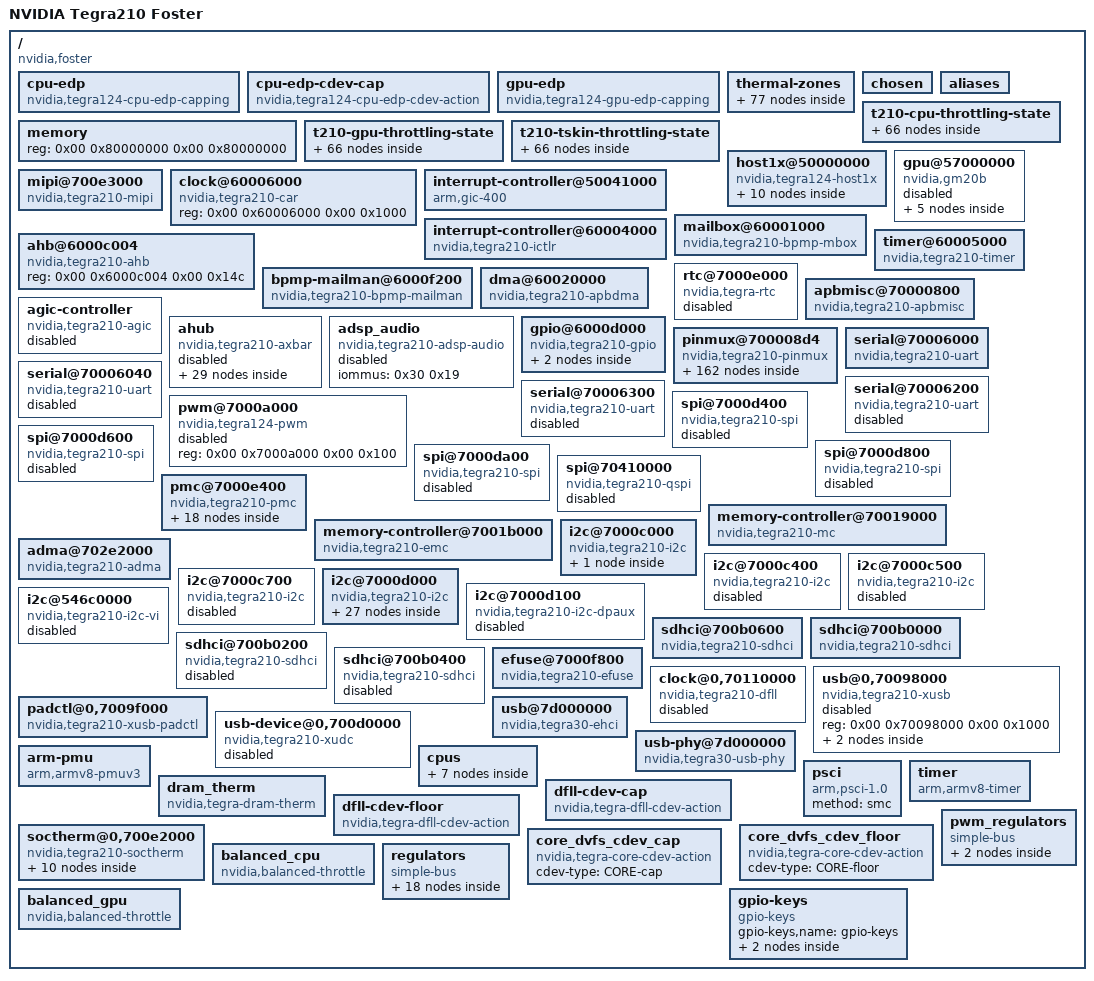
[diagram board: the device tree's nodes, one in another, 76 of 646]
/dts-v1/;

/ {
	#address-cells = <0x02>;
	#size-cells = <0x02>;
	compatible = "nvidia,foster\0nvidia,tegra210";
	interrupt-parent = <0x01>;
	model = "NVIDIA Tegra210 Foster";

	cpu-edp {
		compatible = "nvidia,tegra124-cpu-edp-capping";
		nvidia,freq-step = <0x124f800>;
		nvidia,tegra-ppm-cdyn = <0xe7ef0 0x15be68 0x286f90 0x2faf08>;
		nvidia,tegra-ppm-leakage_weights = <0x1d6 0x29e 0x37a 0x41a>;
		nvidia,tegra-ppm-min_leakage = <0x1e>;
		nvidia,tegra-ppm-coeff_scale = <0x3e8>;
		nvidia,tegra-ppm-leakage_coeffs = <0xffc82924 0xffd15972 0x188c70 0xfffe0053 0x00 0xfe9296 0xff9ec369 0x76883 0xdf9e1a 0xfe718cfb 0x7d365d 0xfff6fa5b 0xff5d899f 0xbbd7ba 0xffcbfa66 0x3958e 0xff87e7c6 0x8b1416 0xffd7e55c 0x2d28a 0x23f3784 0xfdd26ebd 0x948221 0xfff5df7d 0xfcb4b1d2 0x2d60663 0xff4afd55 0xbfe6c 0x17e635c 0xfed015c0 0x47eafe 0xfffb5b77 0x6941d8 0xffaff1ed 0x127eea 0xfffecc39 0xfe70f0f7 0x12565d9 0xffbe1614 0x4381d 0x1f004d1 0xfe9e0b74 0x4d73de 0xfffb1db3 0xff3780c3 0x8ba0fd 0xffe229eb 0x1daf0 0xfff38a0a 0x8b4fd 0xfffe1d49 0x1e56 0x2d5f9e 0xffe0d6d7 0x6a1be 0xffff9672 0xffc99836 0x24c1ff 0xfff84f1f 0x791b 0x155857 0xfff1c880 0x2ed60 0xffffd261>;
		nvidia,tz = <0x02>;
		linux,phandle = <0x03>;
		phandle = <0x03>;
	};

	cpu-edp-cdev-cap {
		compatible = "nvidia,tegra124-cpu-edp-cdev-action";
		act-dev = <0x03>;
		cdev-type = "CPU-EDP-cap";
		#cooling-cells = <0x02>;
		linux,phandle = <0x07>;
		phandle = <0x07>;
	};

	gpu-edp {
		compatible = "nvidia,tegra124-gpu-edp-capping";
		nvidia,freq-step = <0x249f000>;
		nvidia,tegra-ppm-cdyn = <0xe92780>;
		nvidia,tegra-ppm-min_leakage = <0x1e>;
		nvidia,tegra-ppm-coeff_scale = <0x2710>;
		nvidia,tegra-ppm-leakage_coeffs = <0xfef8e2c1 0x17e889a 0xffbd9c0b 0xb807 0x00 0xfd0f73bb 0x864faf 0x1ee25 0x3edf207 0xd7d9e8 0xffd1cab2 0xfff8d56d 0xfd1d9b5f 0x987ac7 0xffeabd12 0x476ae 0x1763b9c 0xfe680f80 0x36f8cb 0x130f 0xfd61d8f9 0x3f7f583 0xff814d99 0xfffd13a0 0x00 0xfd623768 0x4185ff 0x6d6dc 0x119f867 0x4970a8 0x3ae07 0xfffc45c6 0xfdb3616c 0x167f6fb 0xffcc920a 0x198d0 0x6fc1a76 0xfbb7a001 0x9aade2 0xfffb7d5a 0xf93967d1 0x42ae62d 0xff6c4452 0x3ddd8 0x216db9c 0xfeb57ac0 0x2cae38 0xffff05da 0x5961d4 0xffcc181f 0x7ce63 0xffffaed8 0xfee6666e 0xa37bad 0xffe7820c 0xfb9f 0x11f79af 0xff5931b1 0x18dc9f 0xffff04f7 0xffa0fde9 0x371c8a 0xfff7d487 0x50ba>;
		nvidia,tz = <0x04>;
		linux,phandle = <0x34>;
		phandle = <0x34>;
	};

	thermal-zones {
		status = "okay";

		cpu {
			polling-delay-passive = <0x3e8>;
			polling-delay = <0x00>;
			thermal-sensors = <0x05 0x00>;
			linux,phandle = <0x02>;
			phandle = <0x02>;

			trips {

				cpu_edp@23 {
					temperature = <0x59d8>;
					hysteresis = <0x3e8>;
					type = "active";
					linux,phandle = <0x06>;
					phandle = <0x06>;
				};

				cpu_edp@40 {
					temperature = <0x9c40>;
					hysteresis = <0x3e8>;
					type = "active";
					linux,phandle = <0x08>;
					phandle = <0x08>;
				};

				cpu_edp@50 {
					temperature = <0xc350>;
					hysteresis = <0x3e8>;
					type = "active";
					linux,phandle = <0x09>;
					phandle = <0x09>;
				};

				cpu_edp@60 {
					temperature = <0xea60>;
					hysteresis = <0x3e8>;
					type = "active";
					linux,phandle = <0x0a>;
					phandle = <0x0a>;
				};

				cpu_edp@70 {
					temperature = <0x11170>;
					hysteresis = <0x3e8>;
					type = "active";
					linux,phandle = <0x0b>;
					phandle = <0x0b>;
				};

				cpu_edp@74 {
					temperature = <0x12110>;
					hysteresis = <0x3e8>;
					type = "active";
					linux,phandle = <0x0c>;
					phandle = <0x0c>;
				};

				cpu_edp@78 {
					temperature = <0x130b0>;
					hysteresis = <0x3e8>;
					type = "active";
					linux,phandle = <0x0d>;
					phandle = <0x0d>;
				};

				cpu_edp@82 {
					temperature = <0x14050>;
					hysteresis = <0x3e8>;
					type = "active";
					linux,phandle = <0x0e>;
					phandle = <0x0e>;
				};

				cpu_edp@86 {
					temperature = <0x14ff0>;
					hysteresis = <0x3e8>;
					type = "active";
					linux,phandle = <0x0f>;
					phandle = <0x0f>;
				};

				cpu_edp@90 {
					temperature = <0x15f90>;
					hysteresis = <0x3e8>;
					type = "active";
					linux,phandle = <0x10>;
					phandle = <0x10>;
				};

				cpu_edp@94 {
					temperature = <0x16f30>;
					hysteresis = <0x3e8>;
					type = "active";
					linux,phandle = <0x11>;
					phandle = <0x11>;
				};

				cpu_edp@98 {
					temperature = <0x17ed0>;
					hysteresis = <0x3e8>;
					type = "active";
					linux,phandle = <0x12>;
					phandle = <0x12>;
				};

				cpu_edp@102 {
					temperature = <0x18e70>;
					hysteresis = <0x3e8>;
					type = "active";
					linux,phandle = <0x13>;
					phandle = <0x13>;
				};

				dfll-floor-trip0 {
					temperature = <0x3a98>;
					hysteresis = <0x3e8>;
					type = "active";
					linux,phandle = <0x14>;
					phandle = <0x14>;
				};

				dfll-floor-trip1 {
					temperature = <0x7530>;
					hysteresis = <0x3e8>;
					type = "active";
					linux,phandle = <0x16>;
					phandle = <0x16>;
				};

				dfll-floor-trip2 {
					temperature = <0xc350>;
					hysteresis = <0x3e8>;
					type = "active";
					linux,phandle = <0x17>;
					phandle = <0x17>;
				};

				dfll-floor-trip3 {
					temperature = <0x11170>;
					hysteresis = <0x3e8>;
					type = "active";
					linux,phandle = <0x18>;
					phandle = <0x18>;
				};

				dfll-cap-trip0 {
					temperature = <0x101d0>;
					hysteresis = <0x3e8>;
					type = "active";
					linux,phandle = <0x19>;
					phandle = <0x19>;
				};

				dfll-cap-trip1 {
					temperature = <0x14ff0>;
					hysteresis = <0x3e8>;
					type = "active";
					linux,phandle = <0x1b>;
					phandle = <0x1b>;
				};

				core_dvfs_floor_trip0 {
					temperature = <0x3a98>;
					hysteresis = <0x3e8>;
					type = "active";
					linux,phandle = <0x1c>;
					phandle = <0x1c>;
				};

				core_dvfs_cap_trip0 {
					temperature = <0x14ff0>;
					hysteresis = <0x3e8>;
					type = "active";
					linux,phandle = <0x1e>;
					phandle = <0x1e>;
				};
			};

			cooling-maps {

				map_cpu_edp_23 {
					trip = <0x06>;
					cooling-device = <0x07 0x17 0x17>;
				};

				map_cpu_edp_40 {
					trip = <0x08>;
					cooling-device = <0x07 0x28 0x28>;
				};

				map_cpu_edp_50 {
					trip = <0x09>;
					cooling-device = <0x07 0x32 0x32>;
				};

				map_cpu_edp_60 {
					trip = <0x0a>;
					cooling-device = <0x07 0x3c 0x3c>;
				};

				map_cpu_edp_70 {
					trip = <0x0b>;
					cooling-device = <0x07 0x46 0x46>;
				};

				map_cpu_edp_74 {
					trip = <0x0c>;
					cooling-device = <0x07 0x4a 0x4a>;
				};

				map_cpu_edp_78 {
					trip = <0x0d>;
					cooling-device = <0x07 0x4e 0x4e>;
				};

				map_cpu_edp_82 {
					trip = <0x0e>;
					cooling-device = <0x07 0x52 0x52>;
				};

				map_cpu_edp_86 {
					trip = <0x0f>;
					cooling-device = <0x07 0x56 0x56>;
				};

				map_cpu_edp_90 {
					trip = <0x10>;
					cooling-device = <0x07 0x5a 0x5a>;
				};

				map_cpu_edp_94 {
					trip = <0x11>;
					cooling-device = <0x07 0x5e 0x5e>;
				};

				map_cpu_edp_98 {
					trip = <0x12>;
					cooling-device = <0x07 0x62 0x62>;
				};

				map_cpu_edp_102 {
					trip = <0x13>;
					cooling-device = <0x07 0x66 0x66>;
				};

				map0 {
					trip = <0x14>;
					cooling-device = <0x15 0x01 0x01>;
				};

				map1 {
					trip = <0x16>;
					cooling-device = <0x15 0x02 0x02>;
				};

				map2 {
					trip = <0x17>;
					cooling-device = <0x15 0x03 0x03>;
				};

				map3 {
					trip = <0x18>;
					cooling-device = <0x15 0x04 0x04>;
				};

				map5 {
					trip = <0x19>;
					cooling-device = <0x1a 0x01 0x01>;
				};

				map6 {
					trip = <0x1b>;
					cooling-device = <0x1a 0x02 0x02>;
				};

				core_dvfs_floor_map0 {
					trip = <0x1c>;
					cooling-device = <0x1d 0x01 0x01>;
				};

				core_dvfs_cap_map0 {
					trip = <0x1e>;
					cooling-device = <0x1f 0x01 0x01>;
				};
			};
		};

		gpu {
			polling-delay-passive = <0x3e8>;
			polling-delay = <0x00>;
			thermal-sensors = <0x05 0x02>;
			linux,phandle = <0x04>;
			phandle = <0x04>;

			trips {

				gpu_edp@20 {
					temperature = <0x4e20>;
					hysteresis = <0x3e8>;
					type = "active";
					linux,phandle = <0x20>;
					phandle = <0x20>;
				};

				gpu_edp@35 {
					temperature = <0x88b8>;
					hysteresis = <0x3e8>;
					type = "active";
					linux,phandle = <0x22>;
					phandle = <0x22>;
				};

				gpu_edp@50 {
					temperature = <0xc350>;
					hysteresis = <0x3e8>;
					type = "active";
					linux,phandle = <0x23>;
					phandle = <0x23>;
				};

				gpu_edp@70 {
					temperature = <0x11170>;
					hysteresis = <0x3e8>;
					type = "active";
					linux,phandle = <0x24>;
					phandle = <0x24>;
				};

				gpu_edp@80 {
					temperature = <0x13880>;
					hysteresis = <0x3e8>;
					type = "active";
					linux,phandle = <0x25>;
					phandle = <0x25>;
				};

				gpu_edp@90 {
					temperature = <0x15f90>;
					hysteresis = <0x3e8>;
					type = "active";
					linux,phandle = <0x26>;
					phandle = <0x26>;
				};

				gpu_edp@95 {
					temperature = <0x17318>;
					hysteresis = <0x3e8>;
					type = "active";
					linux,phandle = <0x27>;
					phandle = <0x27>;
				};

				gpu_edp@100 {
					temperature = <0x186a0>;
					hysteresis = <0x3e8>;
					type = "active";
					linux,phandle = <0x28>;
					phandle = <0x28>;
				};

				gpu_edp@105 {
					temperature = <0x19a28>;
					hysteresis = <0x3e8>;
					type = "active";
					linux,phandle = <0x29>;
					phandle = <0x29>;
				};
			};

			cooling-maps {

				map_gpu_edp_20 {
					trip = <0x20>;
					cooling-device = <0x21 0x14 0x14>;
				};

				map_gpu_edp_35 {
					trip = <0x22>;
					cooling-device = <0x21 0x23 0x23>;
				};

				map_gpu_edp_50 {
					trip = <0x23>;
					cooling-device = <0x21 0x32 0x32>;
				};

				map_gpu_edp_70 {
					trip = <0x24>;
					cooling-device = <0x21 0x46 0x46>;
				};

				map_gpu_edp_80 {
					trip = <0x25>;
					cooling-device = <0x21 0x50 0x50>;
				};

				map_gpu_edp_90 {
					trip = <0x26>;
					cooling-device = <0x21 0x5a 0x5a>;
				};

				map_gpu_edp_95 {
					trip = <0x27>;
					cooling-device = <0x21 0x5f 0x5f>;
				};

				map_gpu_edp_100 {
					trip = <0x28>;
					cooling-device = <0x21 0x64 0x64>;
				};

				map_gpu_edp_105 {
					trip = <0x29>;
					cooling-device = <0x21 0x69 0x69>;
				};
			};
		};

		mem {
			polling-delay-passive = <0x00>;
			polling-delay = <0x00>;
			thermal-sensors = <0x05 0x01>;
		};

		pllx {
			polling-delay-passive = <0x00>;
			polling-delay = <0x00>;
			thermal-sensors = <0x05 0x03>;
		};

		dram {
			polling-delay-passive = <0x3e8>;
			polling-delay = <0x00>;
			thermal-sensors = <0x2a>;

			trips {

				trip0 {
					temperature = <0x04>;
					hysteresis = <0x00>;
					type = "passive";
					linux,phandle = <0x2b>;
					phandle = <0x2b>;
				};

				trip1 {
					temperature = <0x05>;
					hysteresis = <0x00>;
					type = "passive";
					linux,phandle = <0x2d>;
					phandle = <0x2d>;
				};

				trip2 {
					temperature = <0x06>;
					hysteresis = <0x00>;
					type = "passive";
					linux,phandle = <0x2e>;
					phandle = <0x2e>;
				};
			};

			cooling-maps {

				map0 {
					trip = <0x2b>;
					cooling-device = <0x2c 0x01 0x01>;
				};

				map1 {
					trip = <0x2d>;
					cooling-device = <0x2c 0x02 0x02>;
				};

				map2 {
					trip = <0x2e>;
					cooling-device = <0x2c 0x03 0x03>;
				};
			};
		};
	};

	chosen {
	};

	aliases {
		isp0 = "/host1x@50000000/ispa@54600000";
		isp1 = "/host1x@50000000/ispb@54680000";
		serial0 = "/serial@70006000";
		serial1 = "/serial@70006040";
		serial2 = "/serial@70006200";
		serial3 = "/serial@70006300";
		qspi6 = "/spi@70410000";
	};

	memory {
		device_type = "memory";
		reg = <0x00 0x80000000 0x00 0x80000000>;
	};

	t210-cpu-throttling-state {
		linux,phandle = <0x31>;
		phandle = <0x31>;

		throt-state@0 {
			cpu-freq = <0x1c677c>;
			gpu-freq = <0xd0408>;
			c3bus-freq = <0x7d000>;
			sclk-freq = <0x5dc00>;
		};

		throt-state@1 {
			cpu-freq = <0x1c03e0>;
			gpu-freq = <0xd0408>;
			c3bus-freq = <0x7d000>;
			sclk-freq = <0x5dc00>;
		};

		throt-state@2 {
			cpu-freq = <0x1ba044>;
			gpu-freq = <0xd0408>;
			c3bus-freq = <0x7d000>;
			sclk-freq = <0x5dc00>;
		};

		throt-state@3 {
			cpu-freq = <0x1b3ca8>;
			gpu-freq = <0xd0408>;
			c3bus-freq = <0x7d000>;
			sclk-freq = <0x5dc00>;
		};

		throt-state@4 {
			cpu-freq = <0x1ad90c>;
			gpu-freq = <0xd0408>;
			c3bus-freq = <0x7d000>;
			sclk-freq = <0x5dc00>;
		};

		throt-state@5 {
			cpu-freq = <0x1a7570>;
			gpu-freq = <0xd0408>;
			c3bus-freq = <0x7d000>;
			sclk-freq = <0x5dc00>;
		};

		throt-state@6 {
			cpu-freq = <0x1a11d4>;
			gpu-freq = <0xd0408>;
			c3bus-freq = <0x7d000>;
			sclk-freq = <0x5dc00>;
		};

		throt-state@7 {
			cpu-freq = <0x19ae38>;
			gpu-freq = <0xd0408>;
			c3bus-freq = <0x7d000>;
			sclk-freq = <0x5dc00>;
		};

		throt-state@8 {
			cpu-freq = <0x194a9c>;
			gpu-freq = <0xd0408>;
			c3bus-freq = <0x7d000>;
			sclk-freq = <0x5dc00>;
		};

		throt-state@9 {
			cpu-freq = <0x18e700>;
			gpu-freq = <0xd0408>;
			c3bus-freq = <0x7d000>;
			sclk-freq = <0x5dc00>;
		};

		throt-state@10 {
			cpu-freq = <0x188364>;
			gpu-freq = <0xccd58>;
			c3bus-freq = <0x7d000>;
			sclk-freq = <0x5dc00>;
		};

		throt-state@11 {
			cpu-freq = <0x181fc8>;
			gpu-freq = <0xc9a90>;
			c3bus-freq = <0x7d000>;
			sclk-freq = <0x5dc00>;
		};

		throt-state@12 {
			cpu-freq = <0x17bc2c>;
			gpu-freq = <0xc63e0>;
			c3bus-freq = <0x7d000>;
			sclk-freq = <0x5dc00>;
		};

		throt-state@13 {
			cpu-freq = <0x175890>;
			gpu-freq = <0xc2d30>;
			c3bus-freq = <0x7d000>;
			sclk-freq = <0x5dc00>;
		};

		throt-state@14 {
			cpu-freq = <0x16f4f4>;
			gpu-freq = <0xbf680>;
			c3bus-freq = <0x7d000>;
			sclk-freq = <0x5dc00>;
		};

		throt-state@15 {
			cpu-freq = <0x169158>;
			gpu-freq = <0xbc3b8>;
			c3bus-freq = <0x7d000>;
			sclk-freq = <0x5dc00>;
		};

		throt-state@16 {
			cpu-freq = <0x162dbc>;
			gpu-freq = <0xb8d08>;
			c3bus-freq = <0x7d000>;
			sclk-freq = <0x5dc00>;
		};

		throt-state@17 {
			cpu-freq = <0x15ca20>;
			gpu-freq = <0xb5658>;
			c3bus-freq = <0x7d000>;
			sclk-freq = <0x5dc00>;
		};

		throt-state@18 {
			cpu-freq = <0x156684>;
			gpu-freq = <0xb1fa8>;
			c3bus-freq = <0x7d000>;
			sclk-freq = <0x5dc00>;
		};

		throt-state@19 {
			cpu-freq = <0x1502e8>;
			gpu-freq = <0xaece0>;
			c3bus-freq = <0x7d000>;
			sclk-freq = <0x5dc00>;
		};

		throt-state@20 {
			cpu-freq = <0x149f4c>;
			gpu-freq = <0xab630>;
			c3bus-freq = <0x7d000>;
			sclk-freq = <0x5dc00>;
		};

		throt-state@21 {
			cpu-freq = <0x143bb0>;
			gpu-freq = <0xa7f80>;
			c3bus-freq = <0x7d000>;
			sclk-freq = <0x5dc00>;
		};

		throt-state@22 {
			cpu-freq = <0x13d814>;
			gpu-freq = <0xa48d0>;
			c3bus-freq = <0x7d000>;
			sclk-freq = <0x5dc00>;
		};

		throt-state@23 {
			cpu-freq = <0x137478>;
			gpu-freq = <0xa1608>;
			c3bus-freq = <0x7d000>;
			sclk-freq = <0x5dc00>;
		};

		throt-state@24 {
			cpu-freq = <0x1310dc>;
			gpu-freq = <0x9df58>;
			c3bus-freq = <0x7d000>;
			sclk-freq = <0x5dc00>;
		};

		throt-state@25 {
			cpu-freq = <0x12ad40>;
			gpu-freq = <0x9a8a8>;
			c3bus-freq = <0x7d000>;
			sclk-freq = <0x5dc00>;
		};

		throt-state@26 {
			cpu-freq = <0x1249a4>;
			gpu-freq = <0x975e0>;
			c3bus-freq = <0x7d000>;
			sclk-freq = <0x5dc00>;
		};

		throt-state@27 {
			cpu-freq = <0x11e608>;
			gpu-freq = <0x93f30>;
			c3bus-freq = <0x7d000>;
			sclk-freq = <0x5dc00>;
		};

		throt-state@28 {
			cpu-freq = <0x11826c>;
			gpu-freq = <0x90880>;
			c3bus-freq = <0x7d000>;
			sclk-freq = <0x5dc00>;
		};

		throt-state@29 {
			cpu-freq = <0x111ed0>;
			gpu-freq = <0x8d1d0>;
			c3bus-freq = <0x7d000>;
			sclk-freq = <0x5dc00>;
		};

		throt-state@30 {
			cpu-freq = <0x10bb34>;
			gpu-freq = <0x89f08>;
			c3bus-freq = <0x7d000>;
			sclk-freq = <0x5dc00>;
		};

		throt-state@31 {
			cpu-freq = <0x105798>;
			gpu-freq = <0x86858>;
			c3bus-freq = <0x7d000>;
			sclk-freq = <0x5dc00>;
		};

		throt-state@32 {
			cpu-freq = <0xff3fc>;
			gpu-freq = <0x831a8>;
			c3bus-freq = <0x7d000>;
			sclk-freq = <0x5dc00>;
		};

		throt-state@33 {
			cpu-freq = <0xf9060>;
			gpu-freq = <0x7faf8>;
			c3bus-freq = <0x7d000>;
			sclk-freq = <0x5dc00>;
		};

		throt-state@34 {
			cpu-freq = <0xf2cc4>;
			gpu-freq = <0x7c830>;
			c3bus-freq = <0x7d000>;
			sclk-freq = <0x5dc00>;
		};

		throt-state@35 {
			cpu-freq = <0xec928>;
			gpu-freq = <0x79180>;
			c3bus-freq = "\0\al";
			sclk-freq = <0x5dc00>;
		};

		throt-state@36 {
			cpu-freq = <0xe658c>;
			gpu-freq = <0x75ad0>;
			c3bus-freq = "\0\al";
			sclk-freq = <0x5dc00>;
		};

		throt-state@37 {
			cpu-freq = <0xe01f0>;
			gpu-freq = <0x72808>;
			c3bus-freq = "\0\al";
			sclk-freq = <0x5dc00>;
		};

		throt-state@38 {
			cpu-freq = <0xd9e54>;
			gpu-freq = <0x6f158>;
			c3bus-freq = "\0\al";
			sclk-freq = <0x5dc00>;
		};

		throt-state@39 {
			cpu-freq = <0xd3ab8>;
			gpu-freq = <0x6baa8>;
			c3bus-freq = "\0\al";
			sclk-freq = <0x5dc00>;
		};

		throt-state@40 {
			cpu-freq = <0xcd71c>;
			gpu-freq = <0x683f8>;
			c3bus-freq = "\0\al";
			sclk-freq = <0x5dc00>;
		};

		throt-state@41 {
			cpu-freq = <0xc7380>;
			gpu-freq = <0x65130>;
			c3bus-freq = "\0\al";
			sclk-freq = <0x5dc00>;
		};

		throt-state@42 {
			cpu-freq = <0xc0fe4>;
			gpu-freq = <0x61a80>;
			c3bus-freq = "\0\al";
			sclk-freq = <0x5dc00>;
		};

		throt-state@43 {
			cpu-freq = <0xbac48>;
			gpu-freq = <0x5e3d0>;
			c3bus-freq = "\0\al";
			sclk-freq = <0x5dc00>;
		};

		throt-state@44 {
			cpu-freq = <0xb48ac>;
			gpu-freq = <0x5ad20>;
			c3bus-freq = "\0\a:";
			sclk-freq = <0x5dc00>;
		};

		throt-state@45 {
			cpu-freq = <0xae510>;
			gpu-freq = <0x57a58>;
			c3bus-freq = "\0\a:";
			sclk-freq = <0x5dc00>;
		};

		throt-state@46 {
			cpu-freq = <0xa8174>;
			gpu-freq = <0x543a8>;
			c3bus-freq = "\0\a:";
			sclk-freq = <0x5dc00>;
		};

		throt-state@47 {
			cpu-freq = <0xa1dd8>;
			gpu-freq = <0x50cf8>;
			c3bus-freq = "\0\a:";
			sclk-freq = <0x5dc00>;
		};

		throt-state@48 {
			cpu-freq = <0x9ba3c>;
			gpu-freq = <0x4d648>;
			c3bus-freq = "\0\a:";
			sclk-freq = <0x5dc00>;
		};

		throt-state@49 {
			cpu-freq = <0x956a0>;
			gpu-freq = <0x4a380>;
			c3bus-freq = "\0\a:";
			sclk-freq = <0x5dc00>;
		};

		throt-state@50 {
			cpu-freq = <0x8f304>;
			gpu-freq = <0x46cd0>;
			c3bus-freq = "\0\a:";
			sclk-freq = <0x5dc00>;
		};

		throt-state@51 {
			cpu-freq = <0x88f68>;
			gpu-freq = <0x43620>;
			c3bus-freq = <0x6a400>;
			sclk-freq = <0x5dc00>;
		};

		throt-state@52 {
			cpu-freq = <0x82bcc>;
			gpu-freq = <0x40358>;
			c3bus-freq = <0x6a400>;
			sclk-freq = <0x5dc00>;
		};

		throt-state@53 {
			cpu-freq = <0x7c830>;
			gpu-freq = <0x3cca8>;
			c3bus-freq = <0x6a400>;
			sclk-freq = <0x5dc00>;
		};

		throt-state@54 {
			cpu-freq = <0x76494>;
			gpu-freq = <0x395f8>;
			c3bus-freq = <0x6a400>;
			sclk-freq = <0x5dc00>;
		};

		throt-state@55 {
			cpu-freq = <0x700f8>;
			gpu-freq = <0x35f48>;
			c3bus-freq = <0x6a400>;
			sclk-freq = <0x5dc00>;
		};

		throt-state@56 {
			cpu-freq = <0x69d5c>;
			gpu-freq = <0x32c80>;
			c3bus-freq = <0x6a400>;
			sclk-freq = <0x5dc00>;
		};

		throt-state@57 {
			cpu-freq = <0x639c0>;
			gpu-freq = <0x2f5d0>;
			c3bus-freq = <0x60e00>;
			sclk-freq = <0x5dc00>;
		};

		throt-state@58 {
			cpu-freq = <0x5d624>;
			gpu-freq = <0x2bf20>;
			c3bus-freq = <0x60e00>;
			sclk-freq = <0x5dc00>;
		};

		throt-state@59 {
			cpu-freq = <0x57288>;
			gpu-freq = <0x28870>;
			c3bus-freq = <0x60e00>;
			sclk-freq = <0x5dc00>;
		};

		throt-state@60 {
			cpu-freq = <0x50eec>;
			gpu-freq = <0x255a8>;
			c3bus-freq = <0x60e00>;
			sclk-freq = <0x5dc00>;
		};

		throt-state@61 {
			cpu-freq = <0x4ab50>;
			gpu-freq = <0x21ef8>;
			c3bus-freq = <0x60e00>;
			sclk-freq = <0x5dc00>;
		};

		throt-state@62 {
			cpu-freq = <0x447b4>;
			gpu-freq = <0x1e848>;
			c3bus-freq = <0x60e00>;
			sclk-freq = <0x5dc00>;
		};

		throt-state@63 {
			cpu-freq = <0x3e418>;
			gpu-freq = <0x1b198>;
			c3bus-freq = <0x60e00>;
			sclk-freq = <0x5dc00>;
		};

		throt-state@64 {
			cpu-freq = <0x3807c>;
			gpu-freq = <0x17ed0>;
			c3bus-freq = <0x60e00>;
			sclk-freq = <0x5dc00>;
		};

		throt-state@65 {
			cpu-freq = <0x31ce0>;
			gpu-freq = <0x14820>;
			c3bus-freq = <0x60e00>;
			sclk-freq = <0x5dc00>;
		};
	};

	t210-gpu-throttling-state {
		linux,phandle = <0x32>;
		phandle = <0x32>;

		throt-state@0 {
			cpu-freq = <0x1c677c>;
			gpu-freq = <0xccd58>;
			c3bus-freq = <0x7d000>;
			sclk-freq = <0x5dc00>;
		};

		throt-state@1 {
			cpu-freq = <0x1c03e0>;
			gpu-freq = <0xc96a8>;
			c3bus-freq = <0x7d000>;
			sclk-freq = <0x5dc00>;
		};

		throt-state@2 {
			cpu-freq = <0x1ba044>;
			gpu-freq = <0xc5c10>;
			c3bus-freq = <0x7d000>;
			sclk-freq = <0x5dc00>;
		};

		throt-state@3 {
			cpu-freq = <0x1b3ca8>;
			gpu-freq = <0xc2560>;
			c3bus-freq = <0x7d000>;
			sclk-freq = <0x5dc00>;
		};

		throt-state@4 {
			cpu-freq = <0x1ad90c>;
			gpu-freq = <0xbeeb0>;
			c3bus-freq = <0x7d000>;
			sclk-freq = <0x5dc00>;
		};

		throt-state@5 {
			cpu-freq = <0x1a7570>;
			gpu-freq = <0xbb800>;
			c3bus-freq = <0x7d000>;
			sclk-freq = <0x5dc00>;
		};

		throt-state@6 {
			cpu-freq = <0x1a11d4>;
			gpu-freq = <0xb7d68>;
			c3bus-freq = <0x7d000>;
			sclk-freq = <0x5dc00>;
		};

		throt-state@7 {
			cpu-freq = <0x19ae38>;
			gpu-freq = <0xb46b8>;
			c3bus-freq = <0x7d000>;
			sclk-freq = <0x5dc00>;
		};

		throt-state@8 {
			cpu-freq = <0x194a9c>;
			gpu-freq = <0xb1008>;
			c3bus-freq = <0x7d000>;
			sclk-freq = <0x5dc00>;
		};

		throt-state@9 {
			cpu-freq = <0x18e700>;
			gpu-freq = <0xad958>;
			c3bus-freq = <0x7d000>;
			sclk-freq = <0x5dc00>;
		};

		throt-state@10 {
			cpu-freq = <0x188364>;
			gpu-freq = <0xa9ec0>;
			c3bus-freq = <0x7d000>;
			sclk-freq = <0x5dc00>;
		};

		throt-state@11 {
			cpu-freq = <0x181fc8>;
			gpu-freq = <0xa6810>;
			c3bus-freq = <0x7d000>;
			sclk-freq = <0x5dc00>;
		};

		throt-state@12 {
			cpu-freq = <0x17bc2c>;
			gpu-freq = <0xa3160>;
			c3bus-freq = <0x7d000>;
			sclk-freq = <0x5dc00>;
		};

		throt-state@13 {
			cpu-freq = <0x175890>;
			gpu-freq = <0x9fab0>;
			c3bus-freq = <0x7d000>;
			sclk-freq = <0x5dc00>;
		};

		throt-state@14 {
			cpu-freq = <0x16f4f4>;
			gpu-freq = <0x9c018>;
			c3bus-freq = <0x7d000>;
			sclk-freq = <0x5dc00>;
		};

		throt-state@15 {
			cpu-freq = <0x169158>;
			gpu-freq = <0x98968>;
			c3bus-freq = <0x7d000>;
			sclk-freq = <0x5dc00>;
		};

		throt-state@16 {
			cpu-freq = <0x162dbc>;
			gpu-freq = <0x952b8>;
			c3bus-freq = <0x7d000>;
			sclk-freq = <0x5dc00>;
		};

		throt-state@17 {
			cpu-freq = <0x15ca20>;
			gpu-freq = <0x91c08>;
			c3bus-freq = <0x7d000>;
			sclk-freq = <0x5dc00>;
		};

		throt-state@18 {
			cpu-freq = <0x156684>;
			gpu-freq = <0x8e170>;
			c3bus-freq = <0x7d000>;
			sclk-freq = <0x5dc00>;
		};

		throt-state@19 {
			cpu-freq = <0x1502e8>;
			gpu-freq = <0x8aac0>;
			c3bus-freq = <0x7d000>;
			sclk-freq = <0x5dc00>;
		};

		throt-state@20 {
			cpu-freq = <0x149f4c>;
			gpu-freq = <0x87410>;
			c3bus-freq = <0x7d000>;
			sclk-freq = <0x5dc00>;
		};

		throt-state@21 {
			cpu-freq = <0x143bb0>;
			gpu-freq = <0x83d60>;
			c3bus-freq = <0x7d000>;
			sclk-freq = <0x5dc00>;
		};

		throt-state@22 {
			cpu-freq = <0x13d814>;
			gpu-freq = <0x802c8>;
			c3bus-freq = <0x7d000>;
			sclk-freq = <0x5dc00>;
		};

		throt-state@23 {
			cpu-freq = <0x137478>;
			gpu-freq = <0x7cc18>;
			c3bus-freq = <0x7d000>;
			sclk-freq = <0x5dc00>;
		};

		throt-state@24 {
			cpu-freq = <0x1310dc>;
			gpu-freq = <0x79568>;
			c3bus-freq = <0x7d000>;
			sclk-freq = <0x5dc00>;
		};

		throt-state@25 {
			cpu-freq = <0x12ad40>;
			gpu-freq = <0x75eb8>;
			c3bus-freq = <0x7d000>;
			sclk-freq = <0x5dc00>;
		};

		throt-state@26 {
			cpu-freq = <0x1249a4>;
			gpu-freq = <0x72808>;
			c3bus-freq = <0x7d000>;
			sclk-freq = <0x5dc00>;
		};

		throt-state@27 {
			cpu-freq = <0x11e608>;
			gpu-freq = <0x6ed70>;
			c3bus-freq = <0x7d000>;
			sclk-freq = <0x5dc00>;
		};

		throt-state@28 {
			cpu-freq = <0x11826c>;
			gpu-freq = <0x6b6c0>;
			c3bus-freq = <0x7d000>;
			sclk-freq = <0x5dc00>;
		};

		throt-state@29 {
			cpu-freq = <0x111ed0>;
			gpu-freq = <0x68010>;
			c3bus-freq = <0x7d000>;
			sclk-freq = <0x5dc00>;
		};

		throt-state@30 {
			cpu-freq = <0x10bb34>;
			gpu-freq = <0x64960>;
			c3bus-freq = <0x7d000>;
			sclk-freq = <0x5dc00>;
		};

		throt-state@31 {
			cpu-freq = <0x105798>;
			gpu-freq = <0x60ec8>;
			c3bus-freq = <0x7d000>;
			sclk-freq = <0x5dc00>;
		};

		throt-state@32 {
			cpu-freq = <0xff3fc>;
			gpu-freq = <0x5d818>;
			c3bus-freq = <0x7d000>;
			sclk-freq = <0x5dc00>;
		};

		throt-state@33 {
			cpu-freq = <0xf9060>;
			gpu-freq = <0x5a168>;
			c3bus-freq = <0x7d000>;
			sclk-freq = <0x5dc00>;
		};

		throt-state@34 {
			cpu-freq = <0xf2cc4>;
			gpu-freq = <0x56ab8>;
			c3bus-freq = <0x7d000>;
			sclk-freq = <0x5dc00>;
		};

		throt-state@35 {
			cpu-freq = <0xec928>;
			gpu-freq = <0x53020>;
			c3bus-freq = "\0\al";
			sclk-freq = <0x5dc00>;
		};

		throt-state@36 {
			cpu-freq = <0xe658c>;
			gpu-freq = <0x4f970>;
			c3bus-freq = "\0\al";
			sclk-freq = <0x5dc00>;
		};

		throt-state@37 {
			cpu-freq = <0xe01f0>;
			gpu-freq = <0x4c2c0>;
			c3bus-freq = "\0\al";
			sclk-freq = <0x5dc00>;
		};

		throt-state@38 {
			cpu-freq = <0xd9e54>;
			gpu-freq = <0x48c10>;
			c3bus-freq = "\0\al";
			sclk-freq = <0x5dc00>;
		};

		throt-state@39 {
			cpu-freq = <0xd3ab8>;
			gpu-freq = <0x45178>;
			c3bus-freq = "\0\al";
			sclk-freq = <0x5dc00>;
		};

		throt-state@40 {
			cpu-freq = <0xcd71c>;
			gpu-freq = <0x41ac8>;
			c3bus-freq = "\0\al";
			sclk-freq = <0x5dc00>;
		};

		throt-state@41 {
			cpu-freq = <0xc7380>;
			gpu-freq = <0x3e418>;
			c3bus-freq = "\0\al";
			sclk-freq = <0x5dc00>;
		};

		throt-state@42 {
			cpu-freq = <0xc0fe4>;
			gpu-freq = <0x3ad68>;
			c3bus-freq = "\0\al";
			sclk-freq = <0x5dc00>;
		};

		throt-state@43 {
			cpu-freq = <0xbac48>;
			gpu-freq = <0x372d0>;
			c3bus-freq = "\0\al";
			sclk-freq = <0x5dc00>;
		};

		throt-state@44 {
			cpu-freq = <0xb48ac>;
			gpu-freq = <0x33c20>;
			c3bus-freq = "\0\a:";
			sclk-freq = <0x5dc00>;
		};

		throt-state@45 {
			cpu-freq = <0xae510>;
			gpu-freq = <0x30570>;
			c3bus-freq = "\0\a:";
			sclk-freq = <0x5dc00>;
		};

		throt-state@46 {
			cpu-freq = <0xa8174>;
			gpu-freq = <0x2cec0>;
			c3bus-freq = "\0\a:";
			sclk-freq = <0x5dc00>;
		};

		throt-state@47 {
			cpu-freq = <0xa1dd8>;
			gpu-freq = <0x29428>;
			c3bus-freq = "\0\a:";
			sclk-freq = <0x5dc00>;
		};

		throt-state@48 {
			cpu-freq = <0x9ba3c>;
			gpu-freq = <0x25d78>;
			c3bus-freq = "\0\a:";
			sclk-freq = <0x5dc00>;
		};

		throt-state@49 {
			cpu-freq = <0x956a0>;
			gpu-freq = <0x226c8>;
			c3bus-freq = "\0\a:";
			sclk-freq = <0x5dc00>;
		};

		throt-state@50 {
			cpu-freq = <0x8f304>;
			gpu-freq = <0x1f018>;
			c3bus-freq = "\0\a:";
			sclk-freq = <0x5dc00>;
		};

		throt-state@51 {
			cpu-freq = <0x88f68>;
			gpu-freq = <0x1b580>;
			c3bus-freq = <0x6a400>;
			sclk-freq = <0x5dc00>;
		};

		throt-state@52 {
			cpu-freq = <0x82bcc>;
			gpu-freq = <0x17ed0>;
			c3bus-freq = <0x6a400>;
			sclk-freq = <0x5dc00>;
		};

		throt-state@53 {
			cpu-freq = <0x7c830>;
			gpu-freq = <0x14820>;
			c3bus-freq = <0x6a400>;
			sclk-freq = <0x5dc00>;
		};

		throt-state@54 {
			cpu-freq = <0x76494>;
			gpu-freq = <0x14820>;
			c3bus-freq = <0x6a400>;
			sclk-freq = <0x5dc00>;
		};

		throt-state@55 {
			cpu-freq = <0x700f8>;
			gpu-freq = <0x14820>;
			c3bus-freq = <0x6a400>;
			sclk-freq = <0x5dc00>;
		};

		throt-state@56 {
			cpu-freq = <0x69d5c>;
			gpu-freq = <0x14820>;
			c3bus-freq = <0x6a400>;
			sclk-freq = <0x5dc00>;
		};

		throt-state@57 {
			cpu-freq = <0x639c0>;
			gpu-freq = <0x14820>;
			c3bus-freq = <0x60e00>;
			sclk-freq = <0x5dc00>;
		};

		throt-state@58 {
			cpu-freq = <0x5d624>;
			gpu-freq = <0x14820>;
			c3bus-freq = <0x60e00>;
			sclk-freq = <0x5dc00>;
		};

		throt-state@59 {
			cpu-freq = <0x57288>;
			gpu-freq = <0x14820>;
			c3bus-freq = <0x60e00>;
			sclk-freq = <0x5dc00>;
		};

		throt-state@60 {
			cpu-freq = <0x50eec>;
			gpu-freq = <0x14820>;
			c3bus-freq = <0x60e00>;
			sclk-freq = <0x5dc00>;
		};

		throt-state@61 {
			cpu-freq = <0x4ab50>;
			gpu-freq = <0x14820>;
			c3bus-freq = <0x60e00>;
			sclk-freq = <0x5dc00>;
		};

		throt-state@62 {
			cpu-freq = <0x447b4>;
			gpu-freq = <0x14820>;
			c3bus-freq = <0x60e00>;
			sclk-freq = <0x5dc00>;
		};

		throt-state@63 {
			cpu-freq = <0x3e418>;
			gpu-freq = <0x14820>;
			c3bus-freq = <0x60e00>;
			sclk-freq = <0x5dc00>;
		};

		throt-state@64 {
			cpu-freq = <0x3807c>;
			gpu-freq = <0x14820>;
			c3bus-freq = <0x60e00>;
			sclk-freq = <0x5dc00>;
		};

		throt-state@65 {
			cpu-freq = <0x31ce0>;
			gpu-freq = <0x14820>;
			c3bus-freq = <0x60e00>;
			sclk-freq = <0x5dc00>;
		};
	};

	t210-tskin-throttling-state {
		linux,phandle = <0x33>;
		phandle = <0x33>;

		throt-state@0 {
			cpu-freq = <0x1c677c>;
			gpu-freq = <0xcd528>;
			c3bus-freq = <0x7d000>;
			sclk-freq = <0x5dc00>;
		};

		throt-state@1 {
			cpu-freq = <0x1c03e0>;
			gpu-freq = <0xcaa30>;
			c3bus-freq = <0x7d000>;
			sclk-freq = <0x5dc00>;
		};

		throt-state@2 {
			cpu-freq = <0x1ba044>;
			gpu-freq = <0xc7b50>;
			c3bus-freq = <0x7d000>;
			sclk-freq = <0x5dc00>;
		};

		throt-state@3 {
			cpu-freq = <0x1b3ca8>;
			gpu-freq = <0xc4c70>;
			c3bus-freq = <0x7d000>;
			sclk-freq = <0x5dc00>;
		};

		throt-state@4 {
			cpu-freq = <0x1ad90c>;
			gpu-freq = <0xc2178>;
			c3bus-freq = <0x7d000>;
			sclk-freq = <0x5dc00>;
		};

		throt-state@5 {
			cpu-freq = <0x1a7570>;
			gpu-freq = <0xbf298>;
			c3bus-freq = <0x7d000>;
			sclk-freq = <0x5dc00>;
		};

		throt-state@6 {
			cpu-freq = <0x1a11d4>;
			gpu-freq = <0xbc3b8>;
			c3bus-freq = <0x7d000>;
			sclk-freq = <0x5dc00>;
		};

		throt-state@7 {
			cpu-freq = <0x19ae38>;
			gpu-freq = <0xb98c0>;
			c3bus-freq = <0x7d000>;
			sclk-freq = <0x5dc00>;
		};

		throt-state@8 {
			cpu-freq = <0x194a9c>;
			gpu-freq = <0xb69e0>;
			c3bus-freq = <0x7d000>;
			sclk-freq = <0x5dc00>;
		};

		throt-state@9 {
			cpu-freq = <0x18e700>;
			gpu-freq = "\0\v;";
			c3bus-freq = <0x7d000>;
			sclk-freq = <0x5dc00>;
		};

		throt-state@10 {
			cpu-freq = <0x188364>;
			gpu-freq = <0xb1008>;
			c3bus-freq = <0x7d000>;
			sclk-freq = <0x5dc00>;
		};

		throt-state@11 {
			cpu-freq = <0x181fc8>;
			gpu-freq = <0xae128>;
			c3bus-freq = <0x7d000>;
			sclk-freq = <0x5dc00>;
		};

		throt-state@12 {
			cpu-freq = <0x17bc2c>;
			gpu-freq = <0xab630>;
			c3bus-freq = <0x7d000>;
			sclk-freq = <0x5dc00>;
		};

		throt-state@13 {
			cpu-freq = <0x175890>;
			gpu-freq = <0xa8750>;
			c3bus-freq = <0x7d000>;
			sclk-freq = <0x5dc00>;
		};

		throt-state@14 {
			cpu-freq = <0x16f4f4>;
			gpu-freq = <0xa5870>;
			c3bus-freq = <0x7d000>;
			sclk-freq = <0x5dc00>;
		};

		throt-state@15 {
			cpu-freq = <0x169158>;
			gpu-freq = <0xa2d78>;
			c3bus-freq = <0x7d000>;
			sclk-freq = <0x5dc00>;
		};

		throt-state@16 {
			cpu-freq = <0x162dbc>;
			gpu-freq = <0x9fe98>;
			c3bus-freq = <0x7d000>;
			sclk-freq = <0x5dc00>;
		};

		throt-state@17 {
			cpu-freq = <0x15ca20>;
			gpu-freq = <0x9cfb8>;
			c3bus-freq = <0x7d000>;
			sclk-freq = <0x5dc00>;
		};

		throt-state@18 {
			cpu-freq = <0x156684>;
			gpu-freq = <0x9a4c0>;
			c3bus-freq = <0x7d000>;
			sclk-freq = <0x5dc00>;
		};

		throt-state@19 {
			cpu-freq = <0x1502e8>;
			gpu-freq = <0x975e0>;
			c3bus-freq = <0x7d000>;
			sclk-freq = <0x5dc00>;
		};

		throt-state@20 {
			cpu-freq = <0x149f4c>;
			gpu-freq = "\0\tG";
			c3bus-freq = <0x7d000>;
			sclk-freq = <0x5dc00>;
		};

		throt-state@21 {
			cpu-freq = <0x143bb0>;
			gpu-freq = <0x91c08>;
			c3bus-freq = <0x7d000>;
			sclk-freq = <0x5dc00>;
		};

		throt-state@22 {
			cpu-freq = <0x13d814>;
			gpu-freq = <0x8ed28>;
			c3bus-freq = <0x7d000>;
			sclk-freq = <0x5dc00>;
		};

		throt-state@23 {
			cpu-freq = <0x137478>;
			gpu-freq = <0x8be48>;
			c3bus-freq = <0x7d000>;
			sclk-freq = <0x5dc00>;
		};

		throt-state@24 {
			cpu-freq = <0x1310dc>;
			gpu-freq = <0x89350>;
			c3bus-freq = <0x7d000>;
			sclk-freq = <0x5dc00>;
		};

		throt-state@25 {
			cpu-freq = <0x12ad40>;
			gpu-freq = <0x86470>;
			c3bus-freq = <0x7d000>;
			sclk-freq = <0x5dc00>;
		};

		throt-state@26 {
			cpu-freq = <0x1249a4>;
			gpu-freq = <0x83590>;
			c3bus-freq = <0x7d000>;
			sclk-freq = <0x5dc00>;
		};

		throt-state@27 {
			cpu-freq = <0x11e608>;
			gpu-freq = <0x80a98>;
			c3bus-freq = <0x7d000>;
			sclk-freq = <0x5dc00>;
		};

		throt-state@28 {
			cpu-freq = <0x11826c>;
			gpu-freq = <0x7dbb8>;
			c3bus-freq = <0x7d000>;
			sclk-freq = <0x5dc00>;
		};

		throt-state@29 {
			cpu-freq = <0x111ed0>;
			gpu-freq = <0x7acd8>;
			c3bus-freq = <0x7d000>;
			sclk-freq = <0x5dc00>;
		};

		throt-state@30 {
			cpu-freq = <0x10bb34>;
			gpu-freq = <0x781e0>;
			c3bus-freq = <0x7d000>;
			sclk-freq = <0x5dc00>;
		};

		throt-state@31 {
			cpu-freq = <0x105798>;
			gpu-freq = "\0\aS";
			c3bus-freq = <0x7d000>;
			sclk-freq = <0x5dc00>;
		};

		throt-state@32 {
			cpu-freq = <0xff3fc>;
			gpu-freq = <0x72808>;
			c3bus-freq = <0x7d000>;
			sclk-freq = <0x5dc00>;
		};

		throt-state@33 {
			cpu-freq = <0xf9060>;
			gpu-freq = <0x6f928>;
			c3bus-freq = <0x7d000>;
			sclk-freq = <0x5dc00>;
		};

		throt-state@34 {
			cpu-freq = <0xf2cc4>;
			gpu-freq = <0x6ca48>;
			c3bus-freq = <0x7d000>;
			sclk-freq = <0x5dc00>;
		};

		throt-state@35 {
			cpu-freq = <0xec928>;
			gpu-freq = <0x69f50>;
			c3bus-freq = "\0\al";
			sclk-freq = <0x5dc00>;
		};

		throt-state@36 {
			cpu-freq = <0xe658c>;
			gpu-freq = <0x67070>;
			c3bus-freq = "\0\al";
			sclk-freq = <0x5dc00>;
		};

		throt-state@37 {
			cpu-freq = <0xe01f0>;
			gpu-freq = <0x64190>;
			c3bus-freq = "\0\al";
			sclk-freq = <0x5dc00>;
		};

		throt-state@38 {
			cpu-freq = <0xd9e54>;
			gpu-freq = <0x61698>;
			c3bus-freq = "\0\al";
			sclk-freq = <0x5dc00>;
		};

		throt-state@39 {
			cpu-freq = <0xd3ab8>;
			gpu-freq = <0x5e7b8>;
			c3bus-freq = "\0\al";
			sclk-freq = <0x5dc00>;
		};

		throt-state@40 {
			cpu-freq = <0xcd71c>;
			gpu-freq = <0x5b8d8>;
			c3bus-freq = "\0\al";
			sclk-freq = <0x5dc00>;
		};

		throt-state@41 {
			cpu-freq = <0xc7380>;
			gpu-freq = <0x58de0>;
			c3bus-freq = "\0\al";
			sclk-freq = <0x5dc00>;
		};

		throt-state@42 {
			cpu-freq = <0xc0fe4>;
			gpu-freq = <0x55f00>;
			c3bus-freq = "\0\al";
			sclk-freq = <0x5dc00>;
		};

		throt-state@43 {
			cpu-freq = <0xbac48>;
			gpu-freq = <0x53020>;
			c3bus-freq = "\0\al";
			sclk-freq = <0x5dc00>;
		};

		throt-state@44 {
			cpu-freq = <0xb48ac>;
			gpu-freq = <0x50528>;
			c3bus-freq = "\0\a:";
			sclk-freq = <0x5dc00>;
		};

		throt-state@45 {
			cpu-freq = <0xae510>;
			gpu-freq = <0x4d648>;
			c3bus-freq = "\0\a:";
			sclk-freq = <0x5dc00>;
		};

		throt-state@46 {
			cpu-freq = <0xa8174>;
			gpu-freq = <0x4a768>;
			c3bus-freq = "\0\a:";
			sclk-freq = <0x5dc00>;
		};

		throt-state@47 {
			cpu-freq = <0xa1dd8>;
			gpu-freq = <0x47c70>;
			c3bus-freq = "\0\a:";
			sclk-freq = <0x5dc00>;
		};

		throt-state@48 {
			cpu-freq = <0x9ba3c>;
			gpu-freq = <0x44d90>;
			c3bus-freq = "\0\a:";
			sclk-freq = <0x5dc00>;
		};

		throt-state@49 {
			cpu-freq = <0x956a0>;
			gpu-freq = <0x41eb0>;
			c3bus-freq = "\0\a:";
			sclk-freq = <0x5dc00>;
		};

		throt-state@50 {
			cpu-freq = <0x8f304>;
			gpu-freq = <0x3f3b8>;
			c3bus-freq = "\0\a:";
			sclk-freq = <0x5dc00>;
		};

		throt-state@51 {
			cpu-freq = <0x88f68>;
			gpu-freq = <0x3c4d8>;
			c3bus-freq = <0x6a400>;
			sclk-freq = <0x5dc00>;
		};

		throt-state@52 {
			cpu-freq = <0x82bcc>;
			gpu-freq = <0x395f8>;
			c3bus-freq = <0x6a400>;
			sclk-freq = <0x5dc00>;
		};

		throt-state@53 {
			cpu-freq = <0x7c830>;
			gpu-freq = <0x36b00>;
			c3bus-freq = <0x6a400>;
			sclk-freq = <0x5dc00>;
		};

		throt-state@54 {
			cpu-freq = <0x76494>;
			gpu-freq = <0x33c20>;
			c3bus-freq = <0x6a400>;
			sclk-freq = <0x5dc00>;
		};

		throt-state@55 {
			cpu-freq = <0x700f8>;
			gpu-freq = <0x31128>;
			c3bus-freq = <0x6a400>;
			sclk-freq = <0x5dc00>;
		};

		throt-state@56 {
			cpu-freq = <0x69d5c>;
			gpu-freq = <0x2e248>;
			c3bus-freq = <0x6a400>;
			sclk-freq = <0x5dc00>;
		};

		throt-state@57 {
			cpu-freq = <0x639c0>;
			gpu-freq = <0x2b368>;
			c3bus-freq = <0x60e00>;
			sclk-freq = <0x5dc00>;
		};

		throt-state@58 {
			cpu-freq = <0x5d624>;
			gpu-freq = <0x28870>;
			c3bus-freq = <0x60e00>;
			sclk-freq = <0x5dc00>;
		};

		throt-state@59 {
			cpu-freq = <0x57288>;
			gpu-freq = <0x25990>;
			c3bus-freq = <0x60e00>;
			sclk-freq = <0x5dc00>;
		};

		throt-state@60 {
			cpu-freq = <0x50eec>;
			gpu-freq = <0x22ab0>;
			c3bus-freq = <0x60e00>;
			sclk-freq = <0x5dc00>;
		};

		throt-state@61 {
			cpu-freq = <0x4ab50>;
			gpu-freq = <0x1ffb8>;
			c3bus-freq = <0x60e00>;
			sclk-freq = <0x5dc00>;
		};

		throt-state@62 {
			cpu-freq = <0x447b4>;
			gpu-freq = <0x1d0d8>;
			c3bus-freq = <0x60e00>;
			sclk-freq = <0x5dc00>;
		};

		throt-state@63 {
			cpu-freq = <0x3e418>;
			gpu-freq = <0x1a1f8>;
			c3bus-freq = <0x60e00>;
			sclk-freq = <0x5dc00>;
		};

		throt-state@64 {
			cpu-freq = <0x3807c>;
			gpu-freq = <0x17700>;
			c3bus-freq = <0x60e00>;
			sclk-freq = <0x5dc00>;
		};

		throt-state@65 {
			cpu-freq = <0x31ce0>;
			gpu-freq = <0x14820>;
			c3bus-freq = <0x60e00>;
			sclk-freq = <0x5dc00>;
		};
	};

	host1x@50000000 {
		compatible = "nvidia,tegra124-host1x\0simple-bus";
		reg = <0x00 0x50000000 0x00 0x34000>;
		interrupts = <0x00 0x41 0x04 0x00 0x43 0x04>;
		clocks = <0x2f 0x1c 0x2f 0x77>;
		clock-names = "host1x\0actmon";
		resets = <0x2f 0x1c>;
		reset-names = "host1x";
		#address-cells = <0x02>;
		#size-cells = <0x02>;
		iommus = <0x30 0x06>;
		ranges = <0x00 0x54000000 0x00 0x54000000 0x00 0xc000000>;

		vi@54080000 {
			compatible = "nvidia,tegra210-vi";
			reg = <0x00 0x54080000 0x00 0x40000>;
			interrupts = <0x00 0x45 0x04>;
			clocks = <0x2f 0xe4 0x2f 0x34 0x2f 0x5c 0x2f 0x1b5 0x2f 0x90 0x2f 0x91 0x2f 0x92 0x2f 0xe5 0x2f 0x12a 0x2f 0xab 0x2f 0xfa>;
			clock-names = "vi\0csi\0csus\0sclk\0cilab\0cilcd\0cile\0vi_sensor\0vi_sensor2\0vim2_clk\0pll_d";
			resets = <0x2f 0x14>;
			reset-names = "vi";
			iommus = <0x30 0x17>;
		};

		dc@54200000 {
			compatible = "nvidia,tegra210-dc";
			reg = <0x00 0x54200000 0x00 0x40000>;
			reg-names = "dc";
			interrupts = <0x00 0x49 0x04>;
			clocks = <0x2f 0x1b 0x2f 0xfb 0x2f 0x1c5 0x2f 0x1c7>;
			clock-names = "dc\0parent\0emc\0emc_la";
			resets = <0x2f 0x1b>;
			reset-names = "dc";
			iommus = <0x30 0x01>;
			mc-clients = <0x30 0x01 0x30 0x03 0x30 0x05>;
			nvidia,head = <0x00>;
		};

		dsi@54300000 {
			compatible = "nvidia,tegra210-dsi";
			reg = <0x00 0x54300000 0x00 0x40000>;
			clocks = <0x2f 0x30 0x2f 0x93 0x2f 0xfb>;
			clock-names = "dsi\0lp\0parent";
			resets = <0x2f 0x30>;
			reset-names = "dsi";
			status = "disabled";
		};

		vic@54340000 {
			compatible = "nvidia,tegra210-vic";
			reg = <0x00 0x54340000 0x00 0x40000>;
			clocks = <0x2f 0xb2 0x2f 0x193 0x2f 0x1e2>;
			clock-names = "vic\0vic_cbus\0emc";
			resets = <0x2f 0xb2>;
			reset-names = "vic";
			iommus = <0x30 0x16>;
		};

		nvjpg@54380000 {
			compatible = "nvidia,tegra210-nvjpg";
			reg = <0x00 0x54380000 0x00 0x40000>;
			clocks = <0x2f 0xc3 0x2f 0x194 0x2f 0x1d5>;
			clock-names = "nvjpg\0nvjpg_cbus\0emc";
			resets = <0x2f 0xc3>;
			reset-names = "nvjpg";
			iommus = <0x30 0x1a>;
		};

		dsi@54400000 {
			compatible = "nvidia,tegra210-dsi";
			reg = <0x00 0x54400000 0x00 0x40000>;
			clocks = <0x2f 0x52 0x2f 0x94 0x2f 0xfb>;
			clock-names = "dsi\0lp\0parent";
			resets = <0x2f 0x52>;
			reset-names = "dsi";
			status = "disabled";
		};

		nvdec@54480000 {
			compatible = "nvidia,tegra210-nvdec";
			reg = <0x00 0x54480000 0x00 0x40000>;
			clocks = <0x2f 0xc2 0x2f 0x19e 0x2f 0xc3 0x2f 0x1d6 0x2f 0xe6 0x2f 0x28>;
			clock-names = "nvdec\0nvdec_cbus\0nvjpg\0emc\0fuse\0kfuse";
			resets = <0x2f 0xc2 0x2f 0xc3>;
			reset-names = "nvdec\0nvjpg";
			iommus = <0x30 0x18>;
		};

		nvenc@544c0000 {
			compatible = "nvidia,tegra210-nvenc";
			reg = <0x00 0x544c0000 0x00 0x40000>;
			interrupts = <0x00 0x44 0x04>;
			clocks = <0x2f 0xdb 0x2f 0x19d 0x2f 0x1d4>;
			clock-names = "nvenc\0nvenc_cbus\0emc";
			resets = <0x2f 0xdb>;
			reset-names = "nvenc";
			iommus = <0x30 0x07>;
		};

		ispa@54600000 {
			compatible = "nvidia,tegra210-isp";
			reg = <0x00 0x54600000 0x00 0x40000>;
			interrupts = <0x00 0x47 0x04>;
			clocks = <0x2f 0x17 0x2f 0x1ab 0x2f 0x1dc>;
			clock-names = "isp\0isp_cbus\0emc";
			resets = <0x2f 0x17>;
			reset-names = "isp";
			iommus = <0x30 0x0b>;
		};

		ispb@54680000 {
			compatible = "nvidia,tegra210-isp";
			reg = <0x00 0x54680000 0x00 0x40000>;
			interrupts = <0x00 0x46 0x04>;
			clocks = <0x2f 0x03 0x2f 0x1ac 0x2f 0x1dd>;
			clock-names = "isp\0isp_cbus\0emc";
			resets = <0x2f 0x03>;
			reset-names = "isp";
			iommus = <0x30 0x0e>;
		};
	};

	gpu@57000000 {
		compatible = "nvidia,gm20b";
		reg = <0x00 0x57000000 0x00 0x1000000 0x00 0x58000000 0x00 0x1000000>;
		interrupts = <0x00 0x9d 0x04 0x00 0x9e 0x04>;
		interrupt-names = "stall\0nonstall";
		clocks = <0x2f 0xb8 0x2f 0x12b 0x2f 0xbd 0x2f 0x1d3 0x2f 0xe6>;
		clock-names = "gpu\0pwr\0pllg_ref\0emc\0fuse";
		resets = <0x2f 0xb8>;
		reset-names = "gpu";
		mc = <0x30 0x11>;
		iommus = <0x30 0x11>;
		status = "disabled";

		gpu-scaling-cdev {
			status = "disabled";
			#cooling-cells = <0x02>;
		};

		gpu-balanced-cpu {
			status = "disabled";
			balanced-states = <0x31>;
			#cooling-cells = <0x02>;
		};

		gpu-balanced-gpu {
			status = "disabled";
			balanced-states = <0x32>;
			#cooling-cells = <0x02>;
		};

		gpu-balanced-tskin {
			status = "disabled";
			balanced-states = <0x33>;
			#cooling-cells = <0x02>;
		};

		gpu-edp-cdev {
			act-dev = <0x34>;
			status = "disabled";
			#cooling-cells = <0x02>;
			linux,phandle = <0x21>;
			phandle = <0x21>;
		};
	};

	mipi@700e3000 {
		compatible = "nvidia,tegra210-mipi";
		reg = <0x00 0x700e3000 0x00 0x100>;
		clocks = <0x2f 0x38 0x2f 0xb1>;
		clock-names = "mipi-cal\0parent";
		#nvidia,mipi-calibrate-cells = <0x01>;
	};

	clock@60006000 {
		compatible = "nvidia,tegra210-car\0syscon";
		reg = <0x00 0x60006000 0x00 0x1000>;
		#clock-cells = <0x01>;
		#reset-cells = <0x01>;
		linux,phandle = <0x2f>;
		phandle = <0x2f>;
	};

	interrupt-controller@50041000 {
		compatible = "arm,gic-400";
		#interrupt-cells = <0x03>;
		interrupt-controller;
		interrupt-parent = <0x35>;
		reg = <0x00 0x50041000 0x00 0x1000 0x00 0x50042000 0x00 0x2000 0x00 0x50044000 0x00 0x1000 0x00 0x50046000 0x00 0x2000>;
		interrupts = <0x01 0x09 0xf04>;
		linux,phandle = <0x35>;
		phandle = <0x35>;
	};

	mailbox@60001000 {
		compatible = "nvidia,tegra210-bpmp-mbox";
		reg = <0x00 0x60001000 0x00 0x1000 0x00 0x70016000 0x00 0x1000>;
		reg-names = "sema\0atomics";
		interrupts = <0x00 0x04 0x04 0x00 0x05 0x04 0x00 0x07 0x04 0x00 0x12 0x04 0x00 0x06 0x04>;
		#mbox-cells = <0x01>;
		linux,phandle = <0x36>;
		phandle = <0x36>;
	};

	interrupt-controller@60004000 {
		compatible = "nvidia,tegra210-ictlr\0nvidia,tegra30-ictlr";
		#interrupt-cells = <0x03>;
		interrupt-controller;
		interrupt-parent = <0x35>;
		reg = <0x00 0x60004000 0x00 0x40 0x00 0x60004100 0x00 0x40 0x00 0x60004200 0x00 0x40 0x00 0x60004300 0x00 0x40 0x00 0x60004400 0x00 0x40 0x00 0x60004500 0x00 0x40>;
		linux,phandle = <0x01>;
		phandle = <0x01>;
	};

	timer@60005000 {
		compatible = "nvidia,tegra210-timer\0nvidia,tegra30-timer";
		reg = <0x00 0x60005000 0x00 0x400>;
		interrupts = <0x00 0xb0 0x04 0x00 0xb1 0x04 0x00 0xb2 0x04 0x00 0xb3 0x04>;
		clocks = <0x2f 0x05>;
	};

	ahb@6000c004 {
		compatible = "nvidia,tegra210-ahb\0nvidia,tegra30-ahb";
		reg = <0x00 0x6000c004 0x00 0x14c>;
	};

	bpmp-mailman@6000f200 {
		compatible = "nvidia,tegra210-bpmp-mailman";
		reg = <0x00 0x6000f200 0x00 0x04>;
		reg-names = "cop-reset-vec";
		mboxes = <0x36 0x00 0x36 0x01 0x36 0x02 0x36 0x03 0x36 0x04 0x36 0x05 0x36 0x06 0x36 0x07 0x36 0x08 0x36 0x09 0x36 0x0a 0x36 0x0b>;
		resets = <0x2f 0x01>;
		reset-names = "cop";
		nvidia,bpmp-mbox = <0x36>;
	};

	rtc@7000e000 {
		compatible = "nvidia,tegra-rtc";
		reg = <0x00 0x7000e000 0x00 0x100>;
		interrupts = <0x00 0x02 0x04>;
		status = "disabled";
	};

	dma@60020000 {
		compatible = "nvidia,tegra210-apbdma\0nvidia,tegra148-apbdma";
		reg = <0x00 0x60020000 0x00 0x1400>;
		interrupts = <0x00 0x68 0x04 0x00 0x69 0x04 0x00 0x6a 0x04 0x00 0x6b 0x04 0x00 0x6c 0x04 0x00 0x6d 0x04 0x00 0x6e 0x04 0x00 0x6f 0x04 0x00 0x70 0x04 0x00 0x71 0x04 0x00 0x72 0x04 0x00 0x73 0x04 0x00 0x74 0x04 0x00 0x75 0x04 0x00 0x76 0x04 0x00 0x77 0x04 0x00 0x80 0x04 0x00 0x81 0x04 0x00 0x82 0x04 0x00 0x83 0x04 0x00 0x84 0x04 0x00 0x85 0x04 0x00 0x86 0x04 0x00 0x87 0x04 0x00 0x88 0x04 0x00 0x89 0x04 0x00 0x8a 0x04 0x00 0x8b 0x04 0x00 0x8c 0x04 0x00 0x8d 0x04 0x00 0x8e 0x04 0x00 0x8f 0x04>;
		clocks = <0x2f 0x22>;
		resets = <0x2f 0x22>;
		reset-names = "dma";
		#dma-cells = <0x01>;
		linux,phandle = <0x3b>;
		phandle = <0x3b>;
	};

	apbmisc@70000800 {
		compatible = "nvidia,tegra210-apbmisc\0nvidia,tegra20-apbmisc";
		reg = <0x00 0x70000800 0x00 0x64 0x00 0x70000008 0x00 0x04>;
	};

	agic-controller {
		compatible = "nvidia,tegra210-agic";
		#interrupt-cells = <0x03>;
		interrupt-controller;
		no-gic-extension;
		not-per-cpu;
		reg = <0x00 0x702f9000 0x00 0x2000 0x00 0x702fa000 0x00 0x2000>;
		interrupts = <0x00 0x66 0xf04>;
		status = "disabled";
		linux,phandle = <0x3f>;
		phandle = <0x3f>;
	};

	ahub {
		compatible = "nvidia,tegra210-axbar";
		reg = <0x00 0x702d0800 0x00 0x800>;
		status = "disabled";
		#address-cells = <0x01>;
		#size-cells = <0x01>;
		ranges = <0x702d0000 0x00 0x702d0000 0x10000>;
		clocks = <0x2f 0x6a 0x2f 0xf9 0x2f 0x201>;
		clock-names = "ahub\0pll_a_out0\0xbar.ape";

		admaif@0x702d0000 {
			compatible = "nvidia,tegra210-admaif";
			reg = <0x702d0000 0x800>;
			dmas = <0x37 0x01 0x37 0x01 0x37 0x02 0x37 0x02 0x37 0x03 0x37 0x03 0x37 0x04 0x37 0x04 0x37 0x05 0x37 0x05 0x37 0x06 0x37 0x06 0x37 0x07 0x37 0x07 0x37 0x08 0x37 0x08 0x37 0x09 0x37 0x09 0x37 0x0a 0x37 0x0a>;
			dma-names = "rx1\0tx1\0rx2\0tx2\0rx3\0tx3\0rx4\0tx4\0rx5\0tx5\0rx6\0tx6\0rx7\0tx7\0rx8\0tx8\0rx9\0tx9\0rx10\0tx10";
			status = "disabled";
		};

		sfc@702d2000 {
			compatible = "nvidia,tegra210-sfc";
			reg = <0x702d2000 0x200>;
			nvidia,ahub-sfc-id = <0x00>;
			status = "disabled";
		};

		sfc@702d2200 {
			compatible = "nvidia,tegra210-sfc";
			reg = <0x702d2200 0x200>;
			nvidia,ahub-sfc-id = <0x01>;
			status = "disabled";
		};

		sfc@702d2400 {
			compatible = "nvidia,tegra210-sfc";
			reg = <0x702d2400 0x200>;
			nvidia,ahub-sfc-id = <0x02>;
			status = "disabled";
		};

		sfc@702d2600 {
			compatible = "nvidia,tegra210-sfc";
			reg = <0x702d2600 0x200>;
			nvidia,ahub-sfc-id = <0x03>;
			status = "disabled";
		};

		spkprot@702d8c00 {
			compatible = "nvidia,tegra210-spkprot";
			reg = <0x702d8c00 0x400>;
			nvidia,ahub-spkprot-id = <0x00>;
			status = "disabled";
		};

		amixer@702dbb00 {
			compatible = "nvidia,tegra210-amixer";
			reg = <0x702dbb00 0x800>;
			nvidia,ahub-amixer-id = <0x00>;
			status = "disabled";
		};

		i2s@702d1000 {
			compatible = "nvidia,tegra210-i2s";
			reg = <0x702d1000 0x100>;
			nvidia,ahub-i2s-id = <0x00>;
			clocks = <0x2f 0x1e 0x2f 0x109 0x2f 0x10f 0x2f 0xf9>;
			clock-names = "i2s\0ext_audio_sync\0audio_sync\0pll_a_out0";
			status = "disabled";
		};

		i2s@702d1100 {
			compatible = "nvidia,tegra210-i2s";
			reg = <0x702d1100 0x100>;
			nvidia,ahub-i2s-id = <0x01>;
			clocks = <0x2f 0x0b 0x2f 0x10a 0x2f 0x110 0x2f 0xf9>;
			clock-names = "i2s\0ext_audio_sync\0audio_sync\0pll_a_out0";
			status = "disabled";
		};

		i2s@702d1200 {
			compatible = "nvidia,tegra210-i2s";
			reg = <0x702d1200 0x100>;
			nvidia,ahub-i2s-id = <0x02>;
			clocks = <0x2f 0x12 0x2f 0x10b 0x2f 0x111 0x2f 0xf9>;
			clock-names = "i2s\0ext_audio_sync\0audio_sync\0pll_a_out0";
			status = "disabled";
		};

		i2s@702d1300 {
			compatible = "nvidia,tegra210-i2s";
			reg = <0x702d1300 0x100>;
			nvidia,ahub-i2s-id = <0x03>;
			clocks = <0x2f 0x65 0x2f 0x10c 0x2f 0x112 0x2f 0xf9>;
			clock-names = "i2s\0ext_audio_sync\0audio_sync\0pll_a_out0";
			status = "disabled";
		};

		i2s@702d1400 {
			compatible = "nvidia,tegra210-i2s";
			reg = <0x702d1400 0x100>;
			nvidia,ahub-i2s-id = <0x04>;
			clocks = <0x2f 0x66 0x2f 0x10d 0x2f 0x113 0x2f 0xf9>;
			clock-names = "i2s\0ext_audio_sync\0audio_sync\0pll_a_out0";
			status = "disabled";
		};

		amx@702d3000 {
			compatible = "nvidia,tegra210-amx";
			reg = <0x702d3000 0x100>;
			nvidia,ahub-amx-id = <0x00>;
			status = "disabled";
		};

		amx@702d3100 {
			compatible = "nvidia,tegra210-amx";
			reg = <0x702d3100 0x100>;
			nvidia,ahub-amx-id = <0x01>;
			status = "disabled";
		};

		adx@702d3800 {
			compatible = "nvidia,tegra210-adx";
			reg = <0x702d3800 0x100>;
			nvidia,ahub-adx-id = <0x00>;
			status = "disabled";
		};

		adx@702d3900 {
			compatible = "nvidia,tegra210-adx";
			reg = <0x702d3900 0x100>;
			nvidia,ahub-adx-id = <0x01>;
			status = "disabled";
		};

		afc@702d7000 {
			compatible = "nvidia,tegra210-afc";
			reg = <0x702d7000 0x100>;
			nvidia,ahub-afc-id = <0x00>;
			status = "disabled";
		};

		afc@702d7100 {
			compatible = "nvidia,tegra210-afc";
			reg = <0x702d7100 0x100>;
			nvidia,ahub-afc-id = <0x01>;
			status = "disabled";
		};

		afc@702d7200 {
			compatible = "nvidia,tegra210-afc";
			reg = <0x702d7200 0x100>;
			nvidia,ahub-afc-id = <0x02>;
			status = "disabled";
		};

		afc@702d7300 {
			compatible = "nvidia,tegra210-afc";
			reg = <0x702d7300 0x100>;
			nvidia,ahub-afc-id = <0x03>;
			status = "disabled";
		};

		afc@702d7400 {
			compatible = "nvidia,tegra210-afc";
			reg = <0x702d7400 0x100>;
			nvidia,ahub-afc-id = <0x04>;
			status = "disabled";
		};

		afc@702d7500 {
			compatible = "nvidia,tegra210-afc";
			reg = <0x702d7500 0x100>;
			nvidia,ahub-afc-id = <0x05>;
			status = "disabled";
		};

		mvc@702da000 {
			compatible = "nvidia,tegra210-mvc";
			reg = <0x702da000 0x200>;
			nvidia,ahub-mvc-id = <0x00>;
			status = "disabled";
		};

		mvc@702da200 {
			compatible = "nvidia,tegra210-mvc";
			reg = <0x702da200 0x200>;
			nvidia,ahub-mvc-id = <0x01>;
			status = "disabled";
		};

		spdif@702d6000 {
			compatible = "nvidia,tegra210-spdif";
			reg = <0x702d6000 0x200>;
			nvidia,ahub-spdif-id = <0x00>;
			clocks = <0x2f 0xe2 0x2f 0xe3>;
			clock-names = "spdif_in\0spdif_out";
			status = "disabled";
		};

		iqc@702de000 {
			compatible = "nvidia,tegra210-iqc";
			reg = <0x702de000 0x200>;
			nvidia,ahub-iqc-id = <0x00>;
			status = "disabled";
		};

		iqc@702de200 {
			compatible = "nvidia,tegra210-iqc";
			reg = <0x702de200 0x200>;
			nvidia,ahub-iqc-id = <0x01>;
			status = "disabled";
		};

		ope@702d8000 {
			compatible = "nvidia,tegra210-ope";
			reg = <0x702d8000 0x100 0x702d8100 0x100 0x702d8200 0x200>;
			nvidia,ahub-ope-id = <0x00>;
			status = "disabled";
		};

		ope@702d8400 {
			compatible = "nvidia,tegra210-ope";
			reg = <0x702d8400 0x100 0x702d8500 0x100 0x702d8600 0x200>;
			nvidia,ahub-ope-id = <0x01>;
			status = "disabled";
		};
	};

	adsp_audio {
		compatible = "nvidia,tegra210-adsp-audio";
		iommus = <0x30 0x19>;
		status = "disabled";
	};

	gpio@6000d000 {
		compatible = "nvidia,tegra210-gpio\0nvidia,tegra124-gpio\0nvidia,tegra30-gpio";
		reg = <0x00 0x6000d000 0x00 0x1000>;
		interrupts = <0x00 0x20 0x04 0x00 0x21 0x04 0x00 0x22 0x04 0x00 0x23 0x04 0x00 0x37 0x04 0x00 0x57 0x04 0x00 0x59 0x04 0x00 0x7d 0x04>;
		#gpio-cells = <0x02>;
		gpio-controller;
		#interrupt-cells = <0x02>;
		interrupt-controller;
		gpio-init-names = "default";
		gpio-init-0 = <0x38>;
		gpio-init-1 = <0x39>;
		linux,phandle = <0x40>;
		phandle = <0x40>;

		default {
			gpio-input = <0xdc 0x26 0x05 0xbb 0xbc 0xba 0xb9 0xb8 0xbd 0xbe 0xbf 0xc0 0xc1 0xab 0xc8 0x30 0x50 0x54 0x56 0x3a 0x3d 0x41 0xe6 0xe1>;
			gpio-output-low = <0xda 0xdb 0xe8 0x24 0x25 0x94 0x95 0x96 0x97 0x98 0x99 0xae 0xa9 0xaa 0xad 0xcc 0x32 0x33 0x51 0x52 0x53 0x55 0x57 0x58 0x38 0x3b 0x3c 0x3e 0x3f 0x40 0x42 0x43 0xe7 0xe5>;
			gpio-output-high = <0x27>;
			linux,phandle = <0x38>;
			phandle = <0x38>;
		};

		wlan-default {
			gpio-input = <0x3a 0x41>;
			gpio-output-high = <0x38 0x40>;
			linux,phandle = <0x39>;
			phandle = <0x39>;
		};
	};

	pinmux@700008d4 {
		compatible = "nvidia,tegra210-pinmux";
		reg = <0x00 0x700008d4 0x00 0x2a5 0x00 0x70003000 0x00 0x290>;
		#gpio-range-cells = <0x03>;
		status = "okay";
		pinctrl-names = "default";
		pinctrl-0 = <0x3a>;

		common {
			linux,phandle = <0x3a>;
			phandle = <0x3a>;

			pex_l0_rst_n_pa0 {
				nvidia,pins = "pex_l0_rst_n_pa0";
				nvidia,pull = <0x02>;
				nvidia,tristate = <0x00>;
				nvidia,enable-input = <0x01>;
				nvidia,open-drain = <0x00>;
				nvidia,io-hv = <0x00>;
			};

			pex_l0_clkreq_n_pa1 {
				nvidia,pins = "pex_l0_clkreq_n_pa1";
				nvidia,function = "rsvd1";
				nvidia,pull = <0x01>;
				nvidia,tristate = <0x01>;
				nvidia,enable-input = <0x00>;
				nvidia,open-drain = <0x00>;
				nvidia,io-hv = <0x00>;
			};

			pex_wake_n_pa2 {
				nvidia,pins = "pex_wake_n_pa2";
				nvidia,function = "rsvd1";
				nvidia,pull = <0x01>;
				nvidia,tristate = <0x01>;
				nvidia,enable-input = <0x00>;
				nvidia,open-drain = <0x00>;
				nvidia,io-hv = <0x00>;
			};

			pex_l1_rst_n_pa3 {
				nvidia,pins = "pex_l1_rst_n_pa3";
				nvidia,function = "rsvd1";
				nvidia,pull = <0x01>;
				nvidia,tristate = <0x01>;
				nvidia,enable-input = <0x00>;
				nvidia,open-drain = <0x00>;
				nvidia,io-hv = <0x00>;
			};

			pex_l1_clkreq_n_pa4 {
				nvidia,pins = "pex_l1_clkreq_n_pa4";
				nvidia,function = "rsvd1";
				nvidia,pull = <0x01>;
				nvidia,tristate = <0x01>;
				nvidia,enable-input = <0x00>;
				nvidia,open-drain = <0x00>;
				nvidia,io-hv = <0x00>;
			};

			sata_led_active_pa5 {
				nvidia,pins = "sata_led_active_pa5";
				nvidia,pull = <0x02>;
				nvidia,tristate = <0x00>;
				nvidia,enable-input = <0x01>;
				nvidia,open-drain = <0x00>;
			};

			pa6 {
				nvidia,pins = "pa6";
				nvidia,function = "rsvd1";
				nvidia,pull = <0x01>;
				nvidia,tristate = <0x01>;
				nvidia,enable-input = <0x00>;
				nvidia,open-drain = <0x00>;
			};

			dap1_fs_pb0 {
				nvidia,pins = "dap1_fs_pb0";
				nvidia,function = "rsvd1";
				nvidia,pull = <0x01>;
				nvidia,tristate = <0x01>;
				nvidia,enable-input = <0x00>;
				nvidia,open-drain = <0x00>;
			};

			dap1_din_pb1 {
				nvidia,pins = "dap1_din_pb1";
				nvidia,function = "rsvd1";
				nvidia,pull = <0x01>;
				nvidia,tristate = <0x01>;
				nvidia,enable-input = <0x00>;
				nvidia,open-drain = <0x00>;
			};

			dap1_dout_pb2 {
				nvidia,pins = "dap1_dout_pb2";
				nvidia,function = "rsvd1";
				nvidia,pull = <0x01>;
				nvidia,tristate = <0x01>;
				nvidia,enable-input = <0x00>;
				nvidia,open-drain = <0x00>;
			};

			dap1_sclk_pb3 {
				nvidia,pins = "dap1_sclk_pb3";
				nvidia,function = "rsvd1";
				nvidia,pull = <0x01>;
				nvidia,tristate = <0x01>;
				nvidia,enable-input = <0x00>;
				nvidia,open-drain = <0x00>;
			};

			spi2_mosi_pb4 {
				nvidia,pins = "spi2_mosi_pb4";
				nvidia,function = "rsvd2";
				nvidia,pull = <0x01>;
				nvidia,tristate = <0x01>;
				nvidia,enable-input = <0x00>;
				nvidia,open-drain = <0x00>;
			};

			spi2_miso_pb5 {
				nvidia,pins = "spi2_miso_pb5";
				nvidia,function = "rsvd2";
				nvidia,pull = <0x01>;
				nvidia,tristate = <0x01>;
				nvidia,enable-input = <0x00>;
				nvidia,open-drain = <0x00>;
			};

			spi2_sck_pb6 {
				nvidia,pins = "spi2_sck_pb6";
				nvidia,function = "rsvd2";
				nvidia,pull = <0x01>;
				nvidia,tristate = <0x01>;
				nvidia,enable-input = <0x00>;
				nvidia,open-drain = <0x00>;
			};

			spi2_cs0_pb7 {
				nvidia,pins = "spi2_cs0_pb7";
				nvidia,function = "rsvd2";
				nvidia,pull = <0x01>;
				nvidia,tristate = <0x01>;
				nvidia,enable-input = <0x00>;
				nvidia,open-drain = <0x00>;
			};

			spi1_mosi_pc0 {
				nvidia,pins = "spi1_mosi_pc0";
				nvidia,function = "rsvd1";
				nvidia,pull = <0x01>;
				nvidia,tristate = <0x01>;
				nvidia,enable-input = <0x00>;
				nvidia,open-drain = <0x00>;
			};

			spi1_miso_pc1 {
				nvidia,pins = "spi1_miso_pc1";
				nvidia,function = "rsvd1";
				nvidia,pull = <0x01>;
				nvidia,tristate = <0x01>;
				nvidia,enable-input = <0x00>;
				nvidia,open-drain = <0x00>;
			};

			spi1_sck_pc2 {
				nvidia,pins = "spi1_sck_pc2";
				nvidia,function = "rsvd1";
				nvidia,pull = <0x01>;
				nvidia,tristate = <0x01>;
				nvidia,enable-input = <0x00>;
				nvidia,open-drain = <0x00>;
			};

			spi1_cs0_pc3 {
				nvidia,pins = "spi1_cs0_pc3";
				nvidia,function = "rsvd1";
				nvidia,pull = <0x01>;
				nvidia,tristate = <0x01>;
				nvidia,enable-input = <0x00>;
				nvidia,open-drain = <0x00>;
			};

			spi1_cs1_pc4 {
				nvidia,pins = "spi1_cs1_pc4";
				nvidia,function = "rsvd1";
				nvidia,pull = <0x01>;
				nvidia,tristate = <0x01>;
				nvidia,enable-input = <0x00>;
				nvidia,open-drain = <0x00>;
			};

			spi4_sck_pc5 {
				nvidia,pins = "spi4_sck_pc5";
				nvidia,function = "rsvd1";
				nvidia,pull = <0x01>;
				nvidia,tristate = <0x01>;
				nvidia,enable-input = <0x00>;
				nvidia,open-drain = <0x00>;
			};

			spi4_cs0_pc6 {
				nvidia,pins = "spi4_cs0_pc6";
				nvidia,function = "rsvd1";
				nvidia,pull = <0x01>;
				nvidia,tristate = <0x01>;
				nvidia,enable-input = <0x00>;
				nvidia,open-drain = <0x00>;
			};

			spi4_mosi_pc7 {
				nvidia,pins = "spi4_mosi_pc7";
				nvidia,function = "rsvd1";
				nvidia,pull = <0x01>;
				nvidia,tristate = <0x01>;
				nvidia,enable-input = <0x00>;
				nvidia,open-drain = <0x00>;
			};

			spi4_miso_pd0 {
				nvidia,pins = "spi4_miso_pd0";
				nvidia,function = "rsvd1";
				nvidia,pull = <0x01>;
				nvidia,tristate = <0x01>;
				nvidia,enable-input = <0x00>;
				nvidia,open-drain = <0x00>;
			};

			uart3_tx_pd1 {
				nvidia,pins = "uart3_tx_pd1";
				nvidia,function = "rsvd2";
				nvidia,pull = <0x01>;
				nvidia,tristate = <0x01>;
				nvidia,enable-input = <0x00>;
				nvidia,open-drain = <0x00>;
			};

			uart3_rx_pd2 {
				nvidia,pins = "uart3_rx_pd2";
				nvidia,function = "rsvd2";
				nvidia,pull = <0x01>;
				nvidia,tristate = <0x01>;
				nvidia,enable-input = <0x00>;
				nvidia,open-drain = <0x00>;
			};

			uart3_rts_pd3 {
				nvidia,pins = "uart3_rts_pd3";
				nvidia,function = "rsvd2";
				nvidia,pull = <0x01>;
				nvidia,tristate = <0x01>;
				nvidia,enable-input = <0x00>;
				nvidia,open-drain = <0x00>;
			};

			uart3_cts_pd4 {
				nvidia,pins = "uart3_cts_pd4";
				nvidia,pull = <0x00>;
				nvidia,tristate = <0x00>;
				nvidia,enable-input = <0x01>;
				nvidia,open-drain = <0x00>;
			};

			dmic1_clk_pe0 {
				nvidia,pins = "dmic1_clk_pe0";
				nvidia,function = "i2s3";
				nvidia,pull = <0x00>;
				nvidia,tristate = <0x00>;
				nvidia,enable-input = <0x01>;
				nvidia,open-drain = <0x00>;
			};

			dmic1_dat_pe1 {
				nvidia,pins = "dmic1_dat_pe1";
				nvidia,function = "i2s3";
				nvidia,pull = <0x00>;
				nvidia,tristate = <0x00>;
				nvidia,enable-input = <0x01>;
				nvidia,open-drain = <0x00>;
			};

			dmic2_clk_pe2 {
				nvidia,pins = "dmic2_clk_pe2";
				nvidia,function = "i2s3";
				nvidia,pull = <0x00>;
				nvidia,tristate = <0x00>;
				nvidia,enable-input = <0x01>;
				nvidia,open-drain = <0x00>;
			};

			dmic2_dat_pe3 {
				nvidia,pins = "dmic2_dat_pe3";
				nvidia,function = "i2s3";
				nvidia,pull = <0x00>;
				nvidia,tristate = <0x00>;
				nvidia,enable-input = <0x01>;
				nvidia,open-drain = <0x00>;
			};

			dmic3_clk_pe4 {
				nvidia,pins = "dmic3_clk_pe4";
				nvidia,pull = <0x00>;
				nvidia,tristate = <0x00>;
				nvidia,enable-input = <0x00>;
				nvidia,open-drain = <0x00>;
			};

			dmic3_dat_pe5 {
				nvidia,pins = "dmic3_dat_pe5";
				nvidia,function = "rsvd2";
				nvidia,pull = <0x01>;
				nvidia,tristate = <0x01>;
				nvidia,enable-input = <0x00>;
				nvidia,open-drain = <0x00>;
			};

			pe6 {
				nvidia,pins = "pe6";
				nvidia,function = "rsvd0";
				nvidia,pull = <0x01>;
				nvidia,tristate = <0x01>;
				nvidia,enable-input = <0x00>;
				nvidia,open-drain = <0x00>;
			};

			pe7 {
				nvidia,pins = "pe7";
				nvidia,function = "pwm3";
				nvidia,pull = <0x00>;
				nvidia,tristate = <0x00>;
				nvidia,enable-input = <0x00>;
				nvidia,open-drain = <0x00>;
			};

			gen3_i2c_scl_pf0 {
				nvidia,pins = "gen3_i2c_scl_pf0";
				nvidia,function = "i2c3";
				nvidia,pull = <0x00>;
				nvidia,tristate = <0x00>;
				nvidia,enable-input = <0x01>;
				nvidia,open-drain = <0x00>;
				nvidia,io-hv = <0x00>;
			};

			gen3_i2c_sda_pf1 {
				nvidia,pins = "gen3_i2c_sda_pf1";
				nvidia,function = "i2c3";
				nvidia,pull = <0x00>;
				nvidia,tristate = <0x00>;
				nvidia,enable-input = <0x01>;
				nvidia,open-drain = <0x00>;
				nvidia,io-hv = <0x00>;
			};

			uart2_tx_pg0 {
				nvidia,pins = "uart2_tx_pg0";
				nvidia,pull = <0x00>;
				nvidia,tristate = <0x00>;
				nvidia,enable-input = <0x01>;
				nvidia,open-drain = <0x00>;
			};

			uart2_rx_pg1 {
				nvidia,pins = "uart2_rx_pg1";
				nvidia,function = "uartb";
				nvidia,pull = <0x01>;
				nvidia,tristate = <0x01>;
				nvidia,enable-input = <0x00>;
				nvidia,open-drain = <0x00>;
			};

			uart2_rts_pg2 {
				nvidia,pins = "uart2_rts_pg2";
				nvidia,function = "rsvd2";
				nvidia,pull = <0x01>;
				nvidia,tristate = <0x01>;
				nvidia,enable-input = <0x00>;
				nvidia,open-drain = <0x00>;
			};

			uart2_cts_pg3 {
				nvidia,pins = "uart2_cts_pg3";
				nvidia,function = "rsvd2";
				nvidia,pull = <0x01>;
				nvidia,tristate = <0x01>;
				nvidia,enable-input = <0x00>;
				nvidia,open-drain = <0x00>;
			};

			wifi_en_ph0 {
				nvidia,pins = "wifi_en_ph0";
				nvidia,pull = <0x00>;
				nvidia,tristate = <0x00>;
				nvidia,enable-input = <0x00>;
				nvidia,open-drain = <0x00>;
			};

			wifi_rst_ph1 {
				nvidia,pins = "wifi_rst_ph1";
				nvidia,function = "rsvd0";
				nvidia,pull = <0x01>;
				nvidia,tristate = <0x01>;
				nvidia,enable-input = <0x00>;
				nvidia,open-drain = <0x00>;
			};

			wifi_wake_ap_ph2 {
				nvidia,pins = "wifi_wake_ap_ph2";
				nvidia,pull = <0x02>;
				nvidia,tristate = <0x00>;
				nvidia,enable-input = <0x01>;
				nvidia,open-drain = <0x00>;
			};

			ap_wake_bt_ph3 {
				nvidia,pins = "ap_wake_bt_ph3";
				nvidia,pull = <0x00>;
				nvidia,tristate = <0x00>;
				nvidia,enable-input = <0x00>;
				nvidia,open-drain = <0x00>;
			};

			bt_rst_ph4 {
				nvidia,pins = "bt_rst_ph4";
				nvidia,pull = <0x00>;
				nvidia,tristate = <0x00>;
				nvidia,enable-input = <0x00>;
				nvidia,open-drain = <0x00>;
			};

			bt_wake_ap_ph5 {
				nvidia,pins = "bt_wake_ap_ph5";
				nvidia,pull = <0x02>;
				nvidia,tristate = <0x00>;
				nvidia,enable-input = <0x01>;
				nvidia,open-drain = <0x00>;
			};

			ph6 {
				nvidia,pins = "ph6";
				nvidia,function = "rsvd0";
				nvidia,pull = <0x01>;
				nvidia,tristate = <0x01>;
				nvidia,enable-input = <0x00>;
				nvidia,open-drain = <0x00>;
			};

			ap_wake_nfc_ph7 {
				nvidia,pins = "ap_wake_nfc_ph7";
				nvidia,function = "rsvd0";
				nvidia,pull = <0x01>;
				nvidia,tristate = <0x01>;
				nvidia,enable-input = <0x00>;
				nvidia,open-drain = <0x00>;
			};

			nfc_en_pi0 {
				nvidia,pins = "nfc_en_pi0";
				nvidia,pull = <0x00>;
				nvidia,tristate = <0x00>;
				nvidia,enable-input = <0x00>;
				nvidia,open-drain = <0x00>;
			};

			nfc_int_pi1 {
				nvidia,pins = "nfc_int_pi1";
				nvidia,pull = <0x00>;
				nvidia,tristate = <0x00>;
				nvidia,enable-input = <0x01>;
				nvidia,open-drain = <0x00>;
			};

			gps_en_pi2 {
				nvidia,pins = "gps_en_pi2";
				nvidia,function = "rsvd0";
				nvidia,pull = <0x01>;
				nvidia,tristate = <0x01>;
				nvidia,enable-input = <0x00>;
				nvidia,open-drain = <0x00>;
			};

			gps_rst_pi3 {
				nvidia,pins = "gps_rst_pi3";
				nvidia,function = "rsvd0";
				nvidia,pull = <0x01>;
				nvidia,tristate = <0x01>;
				nvidia,enable-input = <0x00>;
				nvidia,open-drain = <0x00>;
			};

			uart4_tx_pi4 {
				nvidia,pins = "uart4_tx_pi4";
				nvidia,function = "uartd";
				nvidia,pull = <0x00>;
				nvidia,tristate = <0x00>;
				nvidia,enable-input = <0x00>;
				nvidia,open-drain = <0x00>;
			};

			uart4_rx_pi5 {
				nvidia,pins = "uart4_rx_pi5";
				nvidia,function = "uartd";
				nvidia,pull = <0x00>;
				nvidia,tristate = <0x00>;
				nvidia,enable-input = <0x01>;
				nvidia,open-drain = <0x00>;
			};

			uart4_rts_pi6 {
				nvidia,pins = "uart4_rts_pi6";
				nvidia,function = "uartd";
				nvidia,pull = <0x00>;
				nvidia,tristate = <0x00>;
				nvidia,enable-input = <0x00>;
				nvidia,open-drain = <0x00>;
			};

			uart4_cts_pi7 {
				nvidia,pins = "uart4_cts_pi7";
				nvidia,function = "uartd";
				nvidia,pull = <0x00>;
				nvidia,tristate = <0x00>;
				nvidia,enable-input = <0x01>;
				nvidia,open-drain = <0x00>;
			};

			gen1_i2c_sda_pj0 {
				nvidia,pins = "gen1_i2c_sda_pj0";
				nvidia,function = "i2c1";
				nvidia,pull = <0x00>;
				nvidia,tristate = <0x00>;
				nvidia,enable-input = <0x01>;
				nvidia,open-drain = <0x00>;
				nvidia,io-hv = <0x00>;
			};

			gen1_i2c_scl_pj1 {
				nvidia,pins = "gen1_i2c_scl_pj1";
				nvidia,function = "i2c1";
				nvidia,pull = <0x00>;
				nvidia,tristate = <0x00>;
				nvidia,enable-input = <0x01>;
				nvidia,open-drain = <0x00>;
				nvidia,io-hv = <0x00>;
			};

			gen2_i2c_scl_pj2 {
				nvidia,pins = "gen2_i2c_scl_pj2";
				nvidia,function = "i2c2";
				nvidia,pull = <0x00>;
				nvidia,tristate = <0x00>;
				nvidia,enable-input = <0x01>;
				nvidia,open-drain = <0x00>;
				nvidia,io-hv = <0x01>;
			};

			gen2_i2c_sda_pj3 {
				nvidia,pins = "gen2_i2c_sda_pj3";
				nvidia,function = "i2c2";
				nvidia,pull = <0x00>;
				nvidia,tristate = <0x00>;
				nvidia,enable-input = <0x01>;
				nvidia,open-drain = <0x00>;
				nvidia,io-hv = <0x01>;
			};

			dap4_fs_pj4 {
				nvidia,pins = "dap4_fs_pj4";
				nvidia,function = "rsvd1";
				nvidia,pull = <0x01>;
				nvidia,tristate = <0x01>;
				nvidia,enable-input = <0x00>;
				nvidia,open-drain = <0x00>;
			};

			dap4_din_pj5 {
				nvidia,pins = "dap4_din_pj5";
				nvidia,function = "rsvd1";
				nvidia,pull = <0x01>;
				nvidia,tristate = <0x01>;
				nvidia,enable-input = <0x00>;
				nvidia,open-drain = <0x00>;
			};

			dap4_dout_pj6 {
				nvidia,pins = "dap4_dout_pj6";
				nvidia,function = "rsvd1";
				nvidia,pull = <0x01>;
				nvidia,tristate = <0x01>;
				nvidia,enable-input = <0x00>;
				nvidia,open-drain = <0x00>;
			};

			dap4_sclk_pj7 {
				nvidia,pins = "dap4_sclk_pj7";
				nvidia,function = "rsvd1";
				nvidia,pull = <0x01>;
				nvidia,tristate = <0x01>;
				nvidia,enable-input = <0x00>;
				nvidia,open-drain = <0x00>;
			};

			pk0 {
				nvidia,pins = "pk0";
				nvidia,function = "rsvd2";
				nvidia,pull = <0x01>;
				nvidia,tristate = <0x01>;
				nvidia,enable-input = <0x00>;
				nvidia,open-drain = <0x00>;
			};

			pk1 {
				nvidia,pins = "pk1";
				nvidia,function = "rsvd2";
				nvidia,pull = <0x01>;
				nvidia,tristate = <0x01>;
				nvidia,enable-input = <0x00>;
				nvidia,open-drain = <0x00>;
			};

			pk2 {
				nvidia,pins = "pk2";
				nvidia,function = "rsvd2";
				nvidia,pull = <0x01>;
				nvidia,tristate = <0x01>;
				nvidia,enable-input = <0x00>;
				nvidia,open-drain = <0x00>;
			};

			pk3 {
				nvidia,pins = "pk3";
				nvidia,function = "rsvd2";
				nvidia,pull = <0x01>;
				nvidia,tristate = <0x01>;
				nvidia,enable-input = <0x00>;
				nvidia,open-drain = <0x00>;
			};

			pk4 {
				nvidia,pins = "pk4";
				nvidia,function = "rsvd1";
				nvidia,pull = <0x01>;
				nvidia,tristate = <0x01>;
				nvidia,enable-input = <0x00>;
				nvidia,open-drain = <0x00>;
			};

			pk5 {
				nvidia,pins = "pk5";
				nvidia,function = "rsvd1";
				nvidia,pull = <0x01>;
				nvidia,tristate = <0x01>;
				nvidia,enable-input = <0x00>;
				nvidia,open-drain = <0x00>;
			};

			pk6 {
				nvidia,pins = "pk6";
				nvidia,function = "rsvd1";
				nvidia,pull = <0x01>;
				nvidia,tristate = <0x01>;
				nvidia,enable-input = <0x00>;
				nvidia,open-drain = <0x00>;
			};

			pk7 {
				nvidia,pins = "pk7";
				nvidia,function = "rsvd1";
				nvidia,pull = <0x01>;
				nvidia,tristate = <0x01>;
				nvidia,enable-input = <0x00>;
				nvidia,open-drain = <0x00>;
			};

			pl0 {
				nvidia,pins = "pl0";
				nvidia,function = "rsvd0";
				nvidia,pull = <0x01>;
				nvidia,tristate = <0x01>;
				nvidia,enable-input = <0x00>;
				nvidia,open-drain = <0x00>;
			};

			pl1 {
				nvidia,pins = "pl1";
				nvidia,function = "rsvd1";
				nvidia,pull = <0x01>;
				nvidia,tristate = <0x01>;
				nvidia,enable-input = <0x00>;
				nvidia,open-drain = <0x00>;
			};

			sdmmc1_clk_pm0 {
				nvidia,pins = "sdmmc1_clk_pm0";
				nvidia,function = "sdmmc1";
				nvidia,pull = <0x00>;
				nvidia,tristate = <0x00>;
				nvidia,enable-input = <0x01>;
				nvidia,open-drain = <0x00>;
			};

			sdmmc1_cmd_pm1 {
				nvidia,pins = "sdmmc1_cmd_pm1";
				nvidia,function = "sdmmc1";
				nvidia,pull = <0x02>;
				nvidia,tristate = <0x00>;
				nvidia,enable-input = <0x01>;
				nvidia,open-drain = <0x00>;
			};

			sdmmc1_dat3_pm2 {
				nvidia,pins = "sdmmc1_dat3_pm2";
				nvidia,function = "sdmmc1";
				nvidia,pull = <0x02>;
				nvidia,tristate = <0x00>;
				nvidia,enable-input = <0x01>;
				nvidia,open-drain = <0x00>;
			};

			sdmmc1_dat2_pm3 {
				nvidia,pins = "sdmmc1_dat2_pm3";
				nvidia,function = "sdmmc1";
				nvidia,pull = <0x02>;
				nvidia,tristate = <0x00>;
				nvidia,enable-input = <0x01>;
				nvidia,open-drain = <0x00>;
			};

			sdmmc1_dat1_pm4 {
				nvidia,pins = "sdmmc1_dat1_pm4";
				nvidia,function = "sdmmc1";
				nvidia,pull = <0x02>;
				nvidia,tristate = <0x00>;
				nvidia,enable-input = <0x01>;
				nvidia,open-drain = <0x00>;
			};

			sdmmc1_dat0_pm5 {
				nvidia,pins = "sdmmc1_dat0_pm5";
				nvidia,function = "sdmmc1";
				nvidia,pull = <0x02>;
				nvidia,tristate = <0x00>;
				nvidia,enable-input = <0x01>;
				nvidia,open-drain = <0x00>;
			};

			sdmmc3_clk_pp0 {
				nvidia,pins = "sdmmc3_clk_pp0";
				nvidia,function = "sdmmc3";
				nvidia,pull = <0x00>;
				nvidia,tristate = <0x00>;
				nvidia,enable-input = <0x01>;
				nvidia,open-drain = <0x00>;
			};

			sdmmc3_cmd_pp1 {
				nvidia,pins = "sdmmc3_cmd_pp1";
				nvidia,function = "sdmmc3";
				nvidia,pull = <0x02>;
				nvidia,tristate = <0x00>;
				nvidia,enable-input = <0x01>;
				nvidia,open-drain = <0x00>;
			};

			sdmmc3_dat3_pp2 {
				nvidia,pins = "sdmmc3_dat3_pp2";
				nvidia,function = "sdmmc3";
				nvidia,pull = <0x02>;
				nvidia,tristate = <0x00>;
				nvidia,enable-input = <0x01>;
				nvidia,open-drain = <0x00>;
			};

			sdmmc3_dat2_pp3 {
				nvidia,pins = "sdmmc3_dat2_pp3";
				nvidia,function = "sdmmc3";
				nvidia,pull = <0x02>;
				nvidia,tristate = <0x00>;
				nvidia,enable-input = <0x01>;
				nvidia,open-drain = <0x00>;
			};

			sdmmc3_dat1_pp4 {
				nvidia,pins = "sdmmc3_dat1_pp4";
				nvidia,function = "sdmmc3";
				nvidia,pull = <0x02>;
				nvidia,tristate = <0x00>;
				nvidia,enable-input = <0x01>;
				nvidia,open-drain = <0x00>;
			};

			sdmmc3_dat0_pp5 {
				nvidia,pins = "sdmmc3_dat0_pp5";
				nvidia,function = "sdmmc3";
				nvidia,pull = <0x02>;
				nvidia,tristate = <0x00>;
				nvidia,enable-input = <0x01>;
				nvidia,open-drain = <0x00>;
			};

			cam1_mclk_ps0 {
				nvidia,pins = "cam1_mclk_ps0";
				nvidia,function = "rsvd1";
				nvidia,pull = <0x01>;
				nvidia,tristate = <0x01>;
				nvidia,enable-input = <0x00>;
				nvidia,open-drain = <0x00>;
			};

			cam2_mclk_ps1 {
				nvidia,pins = "cam2_mclk_ps1";
				nvidia,function = "rsvd1";
				nvidia,pull = <0x01>;
				nvidia,tristate = <0x01>;
				nvidia,enable-input = <0x00>;
				nvidia,open-drain = <0x00>;
			};

			cam_i2c_scl_ps2 {
				nvidia,pins = "cam_i2c_scl_ps2";
				nvidia,function = "i2cvi";
				nvidia,pull = <0x00>;
				nvidia,tristate = <0x00>;
				nvidia,enable-input = <0x01>;
				nvidia,open-drain = <0x00>;
				nvidia,io-hv = <0x00>;
			};

			cam_i2c_sda_ps3 {
				nvidia,pins = "cam_i2c_sda_ps3";
				nvidia,function = "i2cvi";
				nvidia,pull = <0x00>;
				nvidia,tristate = <0x00>;
				nvidia,enable-input = <0x01>;
				nvidia,open-drain = <0x00>;
				nvidia,io-hv = <0x00>;
			};

			cam_rst_ps4 {
				nvidia,pins = "cam_rst_ps4";
				nvidia,function = "rsvd1";
				nvidia,pull = <0x01>;
				nvidia,tristate = <0x01>;
				nvidia,enable-input = <0x00>;
				nvidia,open-drain = <0x00>;
			};

			cam_af_en_ps5 {
				nvidia,pins = "cam_af_en_ps5";
				nvidia,function = "rsvd2";
				nvidia,pull = <0x01>;
				nvidia,tristate = <0x01>;
				nvidia,enable-input = <0x00>;
				nvidia,open-drain = <0x00>;
			};

			cam_flash_en_ps6 {
				nvidia,pins = "cam_flash_en_ps6";
				nvidia,function = "rsvd2";
				nvidia,pull = <0x01>;
				nvidia,tristate = <0x01>;
				nvidia,enable-input = <0x00>;
				nvidia,open-drain = <0x00>;
			};

			cam1_pwdn_ps7 {
				nvidia,pins = "cam1_pwdn_ps7";
				nvidia,function = "rsvd1";
				nvidia,pull = <0x01>;
				nvidia,tristate = <0x01>;
				nvidia,enable-input = <0x00>;
				nvidia,open-drain = <0x00>;
			};

			cam2_pwdn_pt0 {
				nvidia,pins = "cam2_pwdn_pt0";
				nvidia,function = "rsvd1";
				nvidia,pull = <0x01>;
				nvidia,tristate = <0x01>;
				nvidia,enable-input = <0x00>;
				nvidia,open-drain = <0x00>;
			};

			cam1_strobe_pt1 {
				nvidia,pins = "cam1_strobe_pt1";
				nvidia,function = "rsvd1";
				nvidia,pull = <0x01>;
				nvidia,tristate = <0x01>;
				nvidia,enable-input = <0x00>;
				nvidia,open-drain = <0x00>;
			};

			uart1_tx_pu0 {
				nvidia,pins = "uart1_tx_pu0";
				nvidia,function = "uarta";
				nvidia,pull = <0x00>;
				nvidia,tristate = <0x00>;
				nvidia,enable-input = <0x00>;
				nvidia,open-drain = <0x00>;
			};

			uart1_rx_pu1 {
				nvidia,pins = "uart1_rx_pu1";
				nvidia,function = "uarta";
				nvidia,pull = <0x02>;
				nvidia,tristate = <0x00>;
				nvidia,enable-input = <0x01>;
				nvidia,open-drain = <0x00>;
			};

			uart1_rts_pu2 {
				nvidia,pins = "uart1_rts_pu2";
				nvidia,function = "uarta";
				nvidia,pull = <0x00>;
				nvidia,tristate = <0x00>;
				nvidia,enable-input = <0x00>;
				nvidia,open-drain = <0x00>;
			};

			uart1_cts_pu3 {
				nvidia,pins = "uart1_cts_pu3";
				nvidia,function = "uarta";
				nvidia,pull = <0x02>;
				nvidia,tristate = <0x00>;
				nvidia,enable-input = <0x01>;
				nvidia,open-drain = <0x00>;
			};

			lcd_bl_pwm_pv0 {
				nvidia,pins = "lcd_bl_pwm_pv0";
				nvidia,function = "pwm0";
				nvidia,pull = <0x00>;
				nvidia,tristate = <0x00>;
				nvidia,enable-input = <0x00>;
				nvidia,open-drain = <0x00>;
			};

			lcd_bl_en_pv1 {
				nvidia,pins = "lcd_bl_en_pv1";
				nvidia,pull = <0x00>;
				nvidia,tristate = <0x00>;
				nvidia,enable-input = <0x00>;
				nvidia,open-drain = <0x00>;
			};

			lcd_rst_pv2 {
				nvidia,pins = "lcd_rst_pv2";
				nvidia,function = "rsvd0";
				nvidia,pull = <0x01>;
				nvidia,tristate = <0x01>;
				nvidia,enable-input = <0x00>;
				nvidia,open-drain = <0x00>;
			};

			lcd_gpio1_pv3 {
				nvidia,pins = "lcd_gpio1_pv3";
				nvidia,function = "rsvd1";
				nvidia,pull = <0x01>;
				nvidia,tristate = <0x01>;
				nvidia,enable-input = <0x00>;
				nvidia,open-drain = <0x00>;
			};

			lcd_gpio2_pv4 {
				nvidia,pins = "lcd_gpio2_pv4";
				nvidia,function = "pwm1";
				nvidia,pull = <0x00>;
				nvidia,tristate = <0x00>;
				nvidia,enable-input = <0x00>;
				nvidia,open-drain = <0x00>;
			};

			ap_ready_pv5 {
				nvidia,pins = "ap_ready_pv5";
				nvidia,function = "rsvd0";
				nvidia,pull = <0x01>;
				nvidia,tristate = <0x01>;
				nvidia,enable-input = <0x00>;
				nvidia,open-drain = <0x00>;
			};

			touch_rst_pv6 {
				nvidia,pins = "touch_rst_pv6";
				nvidia,pull = <0x00>;
				nvidia,tristate = <0x00>;
				nvidia,enable-input = <0x00>;
				nvidia,open-drain = <0x00>;
			};

			touch_clk_pv7 {
				nvidia,pins = "touch_clk_pv7";
				nvidia,function = "rsvd1";
				nvidia,pull = <0x01>;
				nvidia,tristate = <0x01>;
				nvidia,enable-input = <0x00>;
				nvidia,open-drain = <0x00>;
			};

			modem_wake_ap_px0 {
				nvidia,pins = "modem_wake_ap_px0";
				nvidia,function = "rsvd0";
				nvidia,pull = <0x01>;
				nvidia,tristate = <0x01>;
				nvidia,enable-input = <0x00>;
				nvidia,open-drain = <0x00>;
			};

			touch_int_px1 {
				nvidia,pins = "touch_int_px1";
				nvidia,function = "rsvd0";
				nvidia,pull = <0x01>;
				nvidia,tristate = <0x01>;
				nvidia,enable-input = <0x00>;
				nvidia,open-drain = <0x00>;
			};

			motion_int_px2 {
				nvidia,pins = "motion_int_px2";
				nvidia,function = "rsvd0";
				nvidia,pull = <0x01>;
				nvidia,tristate = <0x01>;
				nvidia,enable-input = <0x00>;
				nvidia,open-drain = <0x00>;
			};

			als_prox_int_px3 {
				nvidia,pins = "als_prox_int_px3";
				nvidia,function = "rsvd0";
				nvidia,pull = <0x01>;
				nvidia,tristate = <0x01>;
				nvidia,enable-input = <0x00>;
				nvidia,open-drain = <0x00>;
			};

			temp_alert_px4 {
				nvidia,pins = "temp_alert_px4";
				nvidia,pull = <0x02>;
				nvidia,tristate = <0x00>;
				nvidia,enable-input = <0x01>;
				nvidia,open-drain = <0x00>;
			};

			button_power_on_px5 {
				nvidia,pins = "button_power_on_px5";
				nvidia,function = "rsvd0";
				nvidia,pull = <0x01>;
				nvidia,tristate = <0x01>;
				nvidia,enable-input = <0x00>;
				nvidia,open-drain = <0x00>;
			};

			button_vol_up_px6 {
				nvidia,pins = "button_vol_up_px6";
				nvidia,pull = <0x02>;
				nvidia,tristate = <0x00>;
				nvidia,enable-input = <0x01>;
				nvidia,open-drain = <0x00>;
			};

			button_vol_down_px7 {
				nvidia,pins = "button_vol_down_px7";
				nvidia,pull = <0x02>;
				nvidia,tristate = <0x00>;
				nvidia,enable-input = <0x01>;
				nvidia,open-drain = <0x00>;
			};

			button_slide_sw_py0 {
				nvidia,pins = "button_slide_sw_py0";
				nvidia,function = "rsvd0";
				nvidia,pull = <0x01>;
				nvidia,tristate = <0x01>;
				nvidia,enable-input = <0x00>;
				nvidia,open-drain = <0x00>;
			};

			button_home_py1 {
				nvidia,pins = "button_home_py1";
				nvidia,pull = <0x02>;
				nvidia,tristate = <0x00>;
				nvidia,enable-input = <0x01>;
				nvidia,open-drain = <0x00>;
			};

			lcd_te_py2 {
				nvidia,pins = "lcd_te_py2";
				nvidia,function = "rsvd1";
				nvidia,pull = <0x01>;
				nvidia,tristate = <0x01>;
				nvidia,enable-input = <0x00>;
				nvidia,open-drain = <0x00>;
			};

			pwr_i2c_scl_py3 {
				nvidia,pins = "pwr_i2c_scl_py3";
				nvidia,function = "i2cpmu";
				nvidia,pull = <0x00>;
				nvidia,tristate = <0x00>;
				nvidia,enable-input = <0x01>;
				nvidia,open-drain = <0x00>;
				nvidia,io-hv = <0x00>;
			};

			pwr_i2c_sda_py4 {
				nvidia,pins = "pwr_i2c_sda_py4";
				nvidia,function = "i2cpmu";
				nvidia,pull = <0x00>;
				nvidia,tristate = <0x00>;
				nvidia,enable-input = <0x01>;
				nvidia,open-drain = <0x00>;
				nvidia,io-hv = <0x00>;
			};

			clk_32k_out_py5 {
				nvidia,pins = "clk_32k_out_py5";
				nvidia,function = "soc";
				nvidia,pull = <0x02>;
				nvidia,tristate = <0x00>;
				nvidia,enable-input = <0x01>;
				nvidia,open-drain = <0x00>;
			};

			pz0 {
				nvidia,pins = "pz0";
				nvidia,pull = <0x02>;
				nvidia,tristate = <0x00>;
				nvidia,enable-input = <0x01>;
				nvidia,open-drain = <0x00>;
			};

			pz1 {
				nvidia,pins = "pz1";
				nvidia,function = "sdmmc1";
				nvidia,pull = <0x02>;
				nvidia,tristate = <0x00>;
				nvidia,enable-input = <0x01>;
				nvidia,open-drain = <0x00>;
			};

			pz2 {
				nvidia,pins = "pz2";
				nvidia,function = "rsvd2";
				nvidia,pull = <0x01>;
				nvidia,tristate = <0x01>;
				nvidia,enable-input = <0x00>;
				nvidia,open-drain = <0x00>;
			};

			pz3 {
				nvidia,pins = "pz3";
				nvidia,function = "rsvd1";
				nvidia,pull = <0x01>;
				nvidia,tristate = <0x01>;
				nvidia,enable-input = <0x00>;
				nvidia,open-drain = <0x00>;
			};

			pz4 {
				nvidia,pins = "pz4";
				nvidia,pull = <0x00>;
				nvidia,tristate = <0x00>;
				nvidia,enable-input = <0x00>;
				nvidia,open-drain = <0x00>;
			};

			pz5 {
				nvidia,pins = "pz5";
				nvidia,function = "soc";
				nvidia,pull = <0x02>;
				nvidia,tristate = <0x00>;
				nvidia,enable-input = <0x01>;
				nvidia,open-drain = <0x00>;
			};

			dap2_fs_paa0 {
				nvidia,pins = "dap2_fs_paa0";
				nvidia,function = "i2s2";
				nvidia,pull = <0x00>;
				nvidia,tristate = <0x00>;
				nvidia,enable-input = <0x01>;
				nvidia,open-drain = <0x00>;
			};

			dap2_sclk_paa1 {
				nvidia,pins = "dap2_sclk_paa1";
				nvidia,function = "i2s2";
				nvidia,pull = <0x00>;
				nvidia,tristate = <0x00>;
				nvidia,enable-input = <0x01>;
				nvidia,open-drain = <0x00>;
			};

			dap2_din_paa2 {
				nvidia,pins = "dap2_din_paa2";
				nvidia,function = "i2s2";
				nvidia,pull = <0x00>;
				nvidia,tristate = <0x00>;
				nvidia,enable-input = <0x01>;
				nvidia,open-drain = <0x00>;
			};

			dap2_dout_paa3 {
				nvidia,pins = "dap2_dout_paa3";
				nvidia,function = "i2s2";
				nvidia,pull = <0x00>;
				nvidia,tristate = <0x00>;
				nvidia,enable-input = <0x01>;
				nvidia,open-drain = <0x00>;
			};

			aud_mclk_pbb0 {
				nvidia,pins = "aud_mclk_pbb0";
				nvidia,function = "aud";
				nvidia,pull = <0x00>;
				nvidia,tristate = <0x00>;
				nvidia,enable-input = <0x00>;
				nvidia,open-drain = <0x00>;
			};

			dvfs_pwm_pbb1 {
				nvidia,pins = "dvfs_pwm_pbb1";
				nvidia,function = "cldvfs";
				nvidia,pull = <0x00>;
				nvidia,tristate = <0x01>;
				nvidia,enable-input = <0x00>;
				nvidia,open-drain = <0x00>;
			};

			dvfs_clk_pbb2 {
				nvidia,pins = "dvfs_clk_pbb2";
				nvidia,pull = <0x00>;
				nvidia,tristate = <0x00>;
				nvidia,enable-input = <0x00>;
				nvidia,open-drain = <0x00>;
			};

			gpio_x1_aud_pbb3 {
				nvidia,pins = "gpio_x1_aud_pbb3";
				nvidia,function = "rsvd0";
				nvidia,pull = <0x01>;
				nvidia,tristate = <0x01>;
				nvidia,enable-input = <0x00>;
				nvidia,open-drain = <0x00>;
			};

			gpio_x3_aud_pbb4 {
				nvidia,pins = "gpio_x3_aud_pbb4";
				nvidia,function = "rsvd0";
				nvidia,pull = <0x01>;
				nvidia,tristate = <0x01>;
				nvidia,enable-input = <0x00>;
				nvidia,open-drain = <0x00>;
			};

			hdmi_cec_pcc0 {
				nvidia,pins = "hdmi_cec_pcc0";
				nvidia,function = "cec";
				nvidia,pull = <0x00>;
				nvidia,tristate = <0x00>;
				nvidia,enable-input = <0x01>;
				nvidia,open-drain = <0x00>;
				nvidia,io-hv = <0x01>;
			};

			hdmi_int_dp_hpd_pcc1 {
				nvidia,pins = "hdmi_int_dp_hpd_pcc1";
				nvidia,pull = <0x01>;
				nvidia,tristate = <0x00>;
				nvidia,enable-input = <0x01>;
				nvidia,open-drain = <0x00>;
				nvidia,io-hv = <0x00>;
			};

			spdif_out_pcc2 {
				nvidia,pins = "spdif_out_pcc2";
				nvidia,function = "rsvd1";
				nvidia,pull = <0x01>;
				nvidia,tristate = <0x01>;
				nvidia,enable-input = <0x00>;
				nvidia,open-drain = <0x00>;
			};

			spdif_in_pcc3 {
				nvidia,pins = "spdif_in_pcc3";
				nvidia,pull = <0x00>;
				nvidia,tristate = <0x00>;
				nvidia,enable-input = <0x01>;
				nvidia,open-drain = <0x00>;
			};

			usb_vbus_en0_pcc4 {
				nvidia,pins = "usb_vbus_en0_pcc4";
				nvidia,function = "usb";
				nvidia,pull = <0x00>;
				nvidia,tristate = <0x00>;
				nvidia,enable-input = <0x01>;
				nvidia,open-drain = <0x00>;
				nvidia,io-hv = <0x01>;
			};

			usb_vbus_en1_pcc5 {
				nvidia,pins = "usb_vbus_en1_pcc5";
				nvidia,function = "usb";
				nvidia,pull = <0x00>;
				nvidia,tristate = <0x00>;
				nvidia,enable-input = <0x01>;
				nvidia,open-drain = <0x00>;
				nvidia,io-hv = <0x01>;
			};

			dp_hpd0_pcc6 {
				nvidia,pins = "dp_hpd0_pcc6";
				nvidia,function = "rsvd1";
				nvidia,pull = <0x01>;
				nvidia,tristate = <0x01>;
				nvidia,enable-input = <0x00>;
				nvidia,open-drain = <0x00>;
			};

			pcc7 {
				nvidia,pins = "pcc7";
				nvidia,function = "rsvd0";
				nvidia,pull = <0x01>;
				nvidia,tristate = <0x01>;
				nvidia,enable-input = <0x00>;
				nvidia,open-drain = <0x00>;
				nvidia,io-hv = <0x00>;
			};

			spi2_cs1_pdd0 {
				nvidia,pins = "spi2_cs1_pdd0";
				nvidia,function = "rsvd1";
				nvidia,pull = <0x01>;
				nvidia,tristate = <0x01>;
				nvidia,enable-input = <0x00>;
				nvidia,open-drain = <0x00>;
			};

			qspi_sck_pee0 {
				nvidia,pins = "qspi_sck_pee0";
				nvidia,function = "rsvd1";
				nvidia,pull = <0x01>;
				nvidia,tristate = <0x01>;
				nvidia,enable-input = <0x00>;
				nvidia,open-drain = <0x00>;
			};

			qspi_cs_n_pee1 {
				nvidia,pins = "qspi_cs_n_pee1";
				nvidia,function = "rsvd1";
				nvidia,pull = <0x01>;
				nvidia,tristate = <0x01>;
				nvidia,enable-input = <0x00>;
				nvidia,open-drain = <0x00>;
			};

			qspi_io0_pee2 {
				nvidia,pins = "qspi_io0_pee2";
				nvidia,function = "rsvd1";
				nvidia,pull = <0x01>;
				nvidia,tristate = <0x01>;
				nvidia,enable-input = <0x00>;
				nvidia,open-drain = <0x00>;
			};

			qspi_io1_pee3 {
				nvidia,pins = "qspi_io1_pee3";
				nvidia,function = "rsvd1";
				nvidia,pull = <0x01>;
				nvidia,tristate = <0x01>;
				nvidia,enable-input = <0x00>;
				nvidia,open-drain = <0x00>;
			};

			qspi_io2_pee4 {
				nvidia,pins = "qspi_io2_pee4";
				nvidia,function = "rsvd1";
				nvidia,pull = <0x01>;
				nvidia,tristate = <0x01>;
				nvidia,enable-input = <0x00>;
				nvidia,open-drain = <0x00>;
			};

			qspi_io3_pee5 {
				nvidia,pins = "qspi_io3_pee5";
				nvidia,function = "rsvd1";
				nvidia,pull = <0x01>;
				nvidia,tristate = <0x01>;
				nvidia,enable-input = <0x00>;
				nvidia,open-drain = <0x00>;
			};

			core_pwr_req {
				nvidia,pins = "core_pwr_req";
				nvidia,function = "core";
				nvidia,pull = <0x00>;
				nvidia,tristate = <0x00>;
				nvidia,enable-input = <0x00>;
				nvidia,open-drain = <0x00>;
			};

			cpu_pwr_req {
				nvidia,pins = "cpu_pwr_req";
				nvidia,function = "cpu";
				nvidia,pull = <0x00>;
				nvidia,tristate = <0x00>;
				nvidia,enable-input = <0x00>;
				nvidia,open-drain = <0x00>;
			};

			pwr_int_n {
				nvidia,pins = "pwr_int_n";
				nvidia,function = "pmi";
				nvidia,pull = <0x02>;
				nvidia,tristate = <0x00>;
				nvidia,enable-input = <0x01>;
				nvidia,open-drain = <0x00>;
			};

			clk_32k_in {
				nvidia,pins = "clk_32k_in";
				nvidia,function = "clk";
				nvidia,pull = <0x00>;
				nvidia,tristate = <0x00>;
				nvidia,enable-input = <0x01>;
				nvidia,open-drain = <0x00>;
			};

			jtag_rtck {
				nvidia,pins = "jtag_rtck";
				nvidia,function = "jtag";
				nvidia,pull = <0x00>;
				nvidia,tristate = <0x00>;
				nvidia,enable-input = <0x00>;
				nvidia,open-drain = <0x00>;
			};

			clk_req {
				nvidia,pins = "clk_req";
				nvidia,function = "sys";
				nvidia,pull = <0x00>;
				nvidia,tristate = <0x00>;
				nvidia,enable-input = <0x00>;
				nvidia,open-drain = <0x00>;
			};

			shutdown {
				nvidia,pins = "shutdown";
				nvidia,function = "shutdown";
				nvidia,pull = <0x00>;
				nvidia,tristate = <0x00>;
				nvidia,enable-input = <0x00>;
				nvidia,open-drain = <0x00>;
			};
		};
	};

	serial@70006000 {
		compatible = "nvidia,tegra210-uart\0nvidia,tegra20-uart";
		reg = <0x00 0x70006000 0x00 0x40>;
		reg-shift = <0x02>;
		interrupts = <0x00 0x24 0x04>;
		clocks = <0x2f 0x06>;
		resets = <0x2f 0x06>;
		reset-names = "serial";
		dmas = <0x3b 0x08 0x3b 0x08>;
		dma-names = "rx\0tx";
		status = "okay";
	};

	serial@70006040 {
		compatible = "nvidia,tegra210-uart\0nvidia,tegra20-uart";
		reg = <0x00 0x70006040 0x00 0x40>;
		reg-shift = <0x02>;
		interrupts = <0x00 0x25 0x04>;
		clocks = <0x2f 0xe0>;
		resets = <0x2f 0x07>;
		reset-names = "serial";
		dmas = <0x3b 0x09 0x3b 0x09>;
		dma-names = "rx\0tx";
		status = "disabled";
	};

	serial@70006200 {
		compatible = "nvidia,tegra210-uart\0nvidia,tegra20-uart";
		reg = <0x00 0x70006200 0x00 0x40>;
		reg-shift = <0x02>;
		interrupts = <0x00 0x2e 0x04>;
		clocks = <0x2f 0x37>;
		resets = <0x2f 0x37>;
		reset-names = "serial";
		dmas = <0x3b 0x0a 0x3b 0x0a>;
		dma-names = "rx\0tx";
		status = "disabled";
	};

	serial@70006300 {
		compatible = "nvidia,tegra210-uart\0nvidia,tegra20-uart";
		reg = <0x00 0x70006300 0x00 0x40>;
		reg-shift = <0x02>;
		interrupts = <0x00 0x5a 0x04>;
		clocks = <0x2f 0x41>;
		resets = <0x2f 0x41>;
		reset-names = "serial";
		dmas = <0x3b 0x13 0x3b 0x13>;
		dma-names = "rx\0tx";
		status = "disabled";
	};

	pwm@7000a000 {
		compatible = "nvidia,tegra124-pwm";
		reg = <0x00 0x7000a000 0x00 0x100>;
		#pwm-cells = <0x02>;
		status = "disabled";
		linux,phandle = <0x4a>;
		phandle = <0x4a>;
	};

	spi@7000d400 {
		compatible = "nvidia,tegra210-spi";
		reg = <0x00 0x7000d400 0x00 0x200>;
		interrupts = <0x00 0x3b 0x04>;
		#address-cells = <0x01>;
		#size-cells = <0x00>;
		clocks = <0x2f 0x29>;
		clock-names = "spi";
		resets = <0x2f 0x29>;
		reset-names = "spi";
		dmas = <0x3b 0x0f 0x3b 0x0f>;
		dma-names = "rx\0tx";
		status = "disabled";
	};

	spi@7000d600 {
		compatible = "nvidia,tegra210-spi";
		reg = <0x00 0x7000d600 0x00 0x200>;
		interrupts = <0x00 0x52 0x04>;
		#address-cells = <0x01>;
		#size-cells = <0x00>;
		clocks = <0x2f 0x2c>;
		clock-names = "spi";
		resets = <0x2f 0x2c>;
		reset-names = "spi";
		dmas = <0x3b 0x10 0x3b 0x10>;
		dma-names = "rx\0tx";
		status = "disabled";
	};

	spi@7000d800 {
		compatible = "nvidia,tegra210-spi";
		reg = <0x00 0x7000d800 0x00 0x200>;
		interrupts = <0x00 0x53 0x04>;
		#address-cells = <0x01>;
		#size-cells = <0x00>;
		clocks = <0x2f 0x2e>;
		clock-names = "spi";
		resets = <0x2f 0x2e>;
		reset-names = "spi";
		dmas = <0x3b 0x11 0x3b 0x11>;
		dma-names = "rx\0tx";
		status = "disabled";
	};

	spi@7000da00 {
		compatible = "nvidia,tegra210-spi";
		reg = <0x00 0x7000da00 0x00 0x200>;
		interrupts = <0x00 0x5d 0x04>;
		#address-cells = <0x01>;
		#size-cells = <0x00>;
		clocks = <0x2f 0x44>;
		clock-names = "spi";
		resets = <0x2f 0x44>;
		reset-names = "spi";
		dmas = <0x3b 0x12 0x3b 0x12>;
		dma-names = "rx\0tx";
		status = "disabled";
	};

	spi@70410000 {
		compatible = "nvidia,tegra210-qspi";
		reg = <0x00 0x70410000 0x00 0x1000>;
		interrupts = <0x00 0x0a 0x04>;
		#address-cells = <0x01>;
		#size-cells = <0x00>;
		clocks = <0x2f 0xd3>;
		clock-names = "qspi";
		resets = <0x2f 0xd3>;
		reset-names = "qspi";
		dmas = <0x3b 0x05 0x3b 0x05>;
		dma-names = "rx\0tx";
		status = "disabled";
	};

	pmc@7000e400 {
		compatible = "nvidia,tegra210-pmc";
		reg = <0x00 0x7000e400 0x00 0xc00>;
		clocks = <0x2f 0x125>;
		clock-names = "pclk";
		#nvidia,wake-cells = <0x03>;
		status = "okay";
		nvidia,core-power-req-active-high;
		nvidia,sys-clock-req-active-high;

		powergates {

			venc {
				clocks = <0x2f 0xe4 0x2f 0x34 0x2f 0x90 0x2f 0x91 0x2f 0x92 0x2f 0x17 0x2f 0xd0 0x2f 0xa7 0x2f 0xa8 0x2f 0xc9 0x2f 0xc8 0x2f 0x1c 0x2f 0x171 0x2f 0x172>;
				clock-names = "vi\0csi\0cilab\0cilcd\0cile\0isp\0vi-i2c\0slcg_mc_capa\0slcg_mc_cbpa\0slcg_mc_ccpa\0slcg_mc_cdpa\0slcg_host1x\0slcg_vi_slcg_ovr\0slcg_ispa_slcg_ovr";
				resets = <0x2f 0x14 0x2f 0x34 0x2f 0x17 0x2f 0xd0>;
				reset-names = "vi\0csi\0isp\0vi-i2c";
				swgroups = <0x30 0x17 0x30 0x0b>;
				swgroup-names = "vi\0isp2";
				power-partitions = <0x3c>;
			};

			pcie {
				clocks = <0x2f 0x48 0x2f 0x46 0x2f 0x12c>;
				clock-names = "afi\0pcie\0cml0";
				resets = <0x2f 0x48 0x2f 0x46>;
				reset-names = "afi\0pcie";
				swgroups = <0x30 0x03>;
				swgroup-names = "afi";
			};

			mpe {
				clocks = <0x2f 0xdb 0x2f 0xa7 0x2f 0xa8 0x2f 0xc9 0x2f 0xc8 0x2f 0x175>;
				clock-names = "nvenc\0slcg_mc_capa\0slcg_mc_cbpa\0slcg_mc_ccpa\0slcg_mc_cdpa\0slcg_msenc_slcg_ovr";
				resets = <0x2f 0xdb>;
				reset-names = "nvenc";
				swgroups = <0x30 0x07>;
				swgroup-names = "nvenc";
			};

			sata {
				clocks = <0x2f 0x7b 0x2f 0x12d 0x2f 0x7c 0x2f 0xa7 0x2f 0xa8 0x2f 0xc9 0x2f 0xc8 0x2f 0x17e 0x2f 0x17d 0x2f 0x17c>;
				clock-names = "sata_oob\0cml1\0sata\0slcg_mc_capa\0slcg_mc_cbpa\0slcg_mc_ccpa\0slcg_mc_cdpa\0slcg_sata_slcg_ovr_fpci\0slcg_sata_slcg_ovr_ipfs\0slcg_sata_slcg_ovr";
				resets = <0x2f 0x7b 0x2f 0x7c>;
				reset-names = "sata_oob\0sata";
				swgroups = <0x30 0x09>;
				swgroup-names = "sata";
			};

			sor {
				clocks = <0x2f 0xb6 0x2f 0x30 0x2f 0x52 0x2f 0x38 0x2f 0xb5 0x2f 0xa7 0x2f 0xa8 0x2f 0xc9 0x2f 0xc8 0x2f 0x80 0x2f 0x6f 0x2f 0x1b 0x2f 0x1a 0x2f 0x16f 0x2f 0x170>;
				clock-names = "sor0\0dsia\0dsib\0mipi_cal\0dpaux\0slcg_mc_capa\0slcg_mc_cbpa\0slcg_mc_ccpa\0slcg_mc_cdpa\0slcg_hda2hdmi\0slcg_hda2codec_2x\0slcg_disp1\0slcg_disp2\0slcg_disp1_slcg_ovr\0slcg_disp2_slcg_ovr";
				resets = <0x2f 0xb6 0x2f 0x30 0x2f 0x52 0x2f 0xb5 0x2f 0x38>;
				reset-names = "sor0\0dsia\0dsib\0dpaux\0mipi_cal";
				linux,phandle = <0x3c>;
				phandle = <0x3c>;
			};

			dis {
				clocks = <0x2f 0x1b 0x2f 0xa7 0x2f 0xa8 0x2f 0xc9 0x2f 0xc8 0x2f 0x1c 0x2f 0x16f>;
				clock-names = "disp1\0slcg_mc_capa\0slcg_mc_cbpa\0slcg_mc_ccpa\0slcg_mc_cdpa\0slcg_host1x\0slcg_disp1_slcg_ovr";
				resets = <0x2f 0x1b>;
				reset-names = "disp1";
				swgroups = <0x30 0x01>;
				swgroup-names = "dc";
				power-partitions = <0x3c>;
			};

			disb {
				clocks = <0x2f 0x1a 0x2f 0xa7 0x2f 0xa8 0x2f 0xc9 0x2f 0xc8 0x2f 0x1c 0x2f 0x170>;
				clock-names = "disp2\0slcg_mc_capa\0slcg_mc_cbpa\0slcg_mc_ccpa\0slcg_mc_cdpa\0slcg_host1x\0slcg_disp2_slcg_ovr";
				resets = <0x2f 0x1a>;
				reset-names = "disp2";
				swgroups = <0x30 0x02>;
				swgroup-names = "dcb";
				power-partitions = <0x3c>;
			};

			xusba {
				clocks = <0x2f 0x9c 0x2f 0xa7 0x2f 0xa8 0x2f 0xc9 0x2f 0xc8 0x2f 0x59 0x2f 0x121 0x2f 0x179 0x2f 0x178>;
				clock-names = "xusb_ss\0slcg_mc_capa\0slcg_mc_cbpa\0slcg_mc_ccpa\0slcg_mc_cdpa\0slcg_xusb_host\0slcg_xusb_dev\0slcg_xusb_host_slcg_ovr\0slcg_xusb_dev_slcg_ovr";
				resets = <0x2f 0x9c>;
				reset-names = "xusb_ss";
			};

			xusbb {
				clocks = <0x2f 0x121 0x2f 0xa7 0x2f 0xa8 0x2f 0xc9 0x2f 0xc8 0x2f 0x9c 0x2f 0x59 0x2f 0x179 0x2f 0x178>;
				clock-names = "xusb_dev\0slcg_mc_capa\0slcg_mc_cbpa\0slcg_mc_ccpa\0slcg_mc_cdpa\0slcg_xusb_ss\0slcg_xusb_host\0slcg_xusb_host_slcg_ovr\0slcg_xusb_dev_slcg_ovr";
				resets = <0x2f 0x5f>;
				reset-names = "xusb_dev";
				swgroups = <0x30 0x0d>;
				swgroup-names = "xusb_dev";
			};

			xusbc {
				clocks = <0x2f 0x59 0x2f 0xa7 0x2f 0xa8 0x2f 0xc9 0x2f 0xc8 0x2f 0x9c 0x2f 0x121 0x2f 0x178 0x2f 0x179>;
				clock-names = "xusb_host\0slcg_mc_capa\0slcg_mc_cbpa\0slcg_mc_ccpa\0slcg_mc_cdpa\0slcg_xusb_ss\0slcg_xusb_dev\0slcg_xusb_dev_slcg_ovr\0slcg_xusb_host_slcg_ovr";
				resets = <0x2f 0x59>;
				reset-names = "xusb_host";
				swgroups = <0x30 0x0c>;
				swgroup-names = "xusb_host";
			};

			vic {
				clocks = <0x2f 0xb2 0x2f 0xa7 0x2f 0xa8 0x2f 0xc9 0x2f 0xc8 0x2f 0x177 0x2f 0x1c>;
				clock-names = "vic03\0slcg_mc_capa\0slcg_mc_cbpa\0slcg_mc_ccpa\0slcg_mc_cdpa\0slcg_vic03_slcg_ovr\0slcg_host1x";
				resets = <0x2f 0xb2>;
				reset-names = "vic03";
				swgroups = <0x30 0x16>;
				swgroup-names = "vic";
			};

			nvdec {
				clocks = <0x2f 0xc2 0x2f 0xa7 0x2f 0xa8 0x2f 0xc9 0x2f 0xc8 0x2f 0x174 0x2f 0xc3 0x2f 0x176>;
				clock-names = "nvdec\0slcg_mc_capa\0slcg_mc_cbpa\0slcg_mc_ccpa\0slcg_mc_cdpa\0slcg_nvdec_slcg_ovr\0slcg_nvjpg\0slcg_nvjpg_slcg_ovr";
				resets = <0x2f 0xc2>;
				reset-names = "nvdec";
				swgroups = <0x30 0x18>;
				swgroup-names = "nvdec";
				power-partitions = <0x3d>;
			};

			nvjpg {
				clocks = <0x2f 0xc3 0x2f 0xa7 0x2f 0xa8 0x2f 0xc9 0x2f 0xc8 0x2f 0x176 0x2f 0xc2 0x2f 0x174>;
				clock-names = "nvjpg\0slcg_mc_capa\0slcg_mc_cbpa\0slcg_mc_ccpa\0slcg_mc_cdpa\0slcg_nvjpg_slcg_ovr\0slcg_nvdec\0slcg_nvdec_slcg_ovr";
				resets = <0x2f 0xc3>;
				reset-names = "nvjpg";
				swgroups = <0x30 0x1a>;
				swgroup-names = "nvjpg";
				linux,phandle = <0x3d>;
				phandle = <0x3d>;
			};

			aud {
				clocks = <0x2f 0xc6 0x2f 0xa7 0x2f 0xa8 0x2f 0xc9 0x2f 0xc8 0x2f 0x1e 0x2f 0x0b 0x2f 0x12 0x2f 0x65 0x2f 0x66 0x2f 0xe3 0x2f 0x6a 0x2f 0x17b 0x2f 0x17a>;
				clock-names = "ape\0slcg_mc_capa\0slcg_mc_cbpa\0slcg_mc_ccpa\0slcg_mc_cdpa\0slcg_i2s0\0slcg_i2s1\0slcg_i2s2\0slcg_i2s3\0slcg_i2s4\0slcg_spdif_out\0slcg_d_audio\0slcg_ape_slcg_ovr\0slcg_d_audio_slcg_ovr";
				resets = <0x2f 0xc6>;
				reset-names = "ape";
				swgroups = <0x30 0x19>;
				swgroup-names = "ape";
			};

			ve2 {
				slcg-clk-num = <0x05>;
				clocks = <0x2f 0x03 0x2f 0xa7 0x2f 0xa8 0x2f 0xc9 0x2f 0xc8 0x2f 0x173>;
				clock-names = "ispb\0slcg_mc_capa\0slcg_mc_cbpa\0slcg_mc_ccpa\0slcg_mc_cdpa\0slcg_ispb_slcg_ovr";
				resets = <0x2f 0x03>;
				reset-names = "ispb";
				swgroups = <0x30 0x0e>;
				swgroup-names = "isp2b";
			};

			dfd {
				clocks = <0x2f 0x49 0x2f 0x4c>;
				clock-names = "csite\0la";
				resets = <0x2f 0x49 0x2f 0x4c>;
				reset-names = "csite\0la";
				swgroups = <0x30 0x1d 0x30 0x1c>;
				swgroup-names = "etr\0axiap";
			};
		};

		i2c-thermtrip {
			nvidia,pmu = <0x3e>;
			nvidia,reg-addr = <0x41>;
			nvidia,reg-data = <0x80>;
		};
	};

	memory-controller@70019000 {
		compatible = "nvidia,tegra210-mc";
		reg = <0x00 0x70019000 0x00 0x1000>;
		clocks = <0x2f 0x20 0x2f 0x39>;
		clock-names = "mc\0emc";
		interrupts = <0x00 0x4d 0x04>;
		#iommu-cells = <0x01>;
		#mc-client-cells = <0x01>;
		linux,phandle = <0x30>;
		phandle = <0x30>;
	};

	memory-controller@7001b000 {
		compatible = "nvidia,tegra210-emc";
		reg = <0x00 0x7001b000 0x00 0x1000 0x00 0x7001e000 0x00 0x1000 0x00 0x7001f000 0x00 0x1000>;
		#address-cells = <0x02>;
		#size-cells = <0x02>;
		clocks = <0x2f 0x39 0x2f 0xf1 0x2f 0xed 0x2f 0xf3 0x2f 0xe9 0x2f 0x131 0x2f 0x1e0>;
		clock-names = "emc\0pll_m\0pll_c\0pll_p\0clk_m\0pll_mb\0emc_override";
		#thermal-sensor-cells = <0x00>;
		ranges;
		linux,phandle = <0x2a>;
		phandle = <0x2a>;
	};

	adma@702e2000 {
		compatible = "nvidia,tegra210-adma";
		reg = <0x00 0x702e2000 0x00 0x2000>;
		interrupt-parent = <0x3f>;
		interrupts = <0x00 0x18 0x04 0x00 0x19 0x04 0x00 0x1a 0x04 0x00 0x1b 0x04 0x00 0x1c 0x04 0x00 0x1d 0x04 0x00 0x1e 0x04 0x00 0x1f 0x04 0x00 0x20 0x04 0x00 0x21 0x04>;
		#dma-cells = <0x01>;
		dma-channels = <0x0a>;
		clocks = <0x2f 0x6a 0x2f 0x1ff>;
		clock-names = "adma\0adma.ape";
		status = "okay";
		linux,phandle = <0x37>;
		phandle = <0x37>;
	};

	i2c@7000c000 {
		compatible = "nvidia,tegra210-i2c\0nvidia,tegra124-i2c";
		reg = <0x00 0x7000c000 0x00 0x100>;
		interrupts = <0x00 0x26 0x04>;
		#address-cells = <0x01>;
		#size-cells = <0x00>;
		clocks = <0x2f 0x0c>;
		clock-names = "div-clk";
		resets = <0x2f 0x0c>;
		reset-names = "i2c";
		dmas = <0x3b 0x15 0x3b 0x15>;
		dma-names = "rx\0tx";
		nvidia,controller-id = <0x00>;
		status = "okay";
		clock-frequency = <0x61a80>;

		temperature-sensor@4c {
			compatible = "ti,tmp451";
			reg = <0x4c>;
			interrupt-parent = <0x40>;
			interrupts = <0xbc 0x08>;
			vcc-supply = <0x41>;
			#thermal-sensor-cells = <0x01>;
		};
	};

	i2c@7000c400 {
		compatible = "nvidia,tegra210-i2c\0nvidia,tegra124-i2c";
		reg = <0x00 0x7000c400 0x00 0x100>;
		interrupts = <0x00 0x54 0x04>;
		#address-cells = <0x01>;
		#size-cells = <0x00>;
		clocks = <0x2f 0x36>;
		clock-names = "div-clk";
		resets = <0x2f 0x36>;
		reset-names = "i2c";
		dmas = <0x3b 0x16 0x3b 0x16>;
		dma-names = "rx\0tx";
		nvidia,controller-id = <0x01>;
		status = "disabled";
		clock-frequency = <0x186a0>;
	};

	i2c@7000c500 {
		compatible = "nvidia,tegra210-i2c\0nvidia,tegra124-i2c";
		reg = <0x00 0x7000c500 0x00 0x100>;
		interrupts = <0x00 0x5c 0x04>;
		#address-cells = <0x01>;
		#size-cells = <0x00>;
		clocks = <0x2f 0x43>;
		clock-names = "div-clk";
		resets = <0x2f 0x43>;
		reset-names = "i2c";
		dmas = <0x3b 0x17 0x3b 0x17>;
		dma-names = "rx\0tx";
		nvidia,controller-id = <0x02>;
		status = "disabled";
		clock-frequency = <0x61a80>;
	};

	i2c@7000c700 {
		compatible = "nvidia,tegra210-i2c\0nvidia,tegra124-i2c";
		reg = <0x00 0x7000c700 0x00 0x100>;
		interrupts = <0x00 0x78 0x04>;
		#address-cells = <0x01>;
		#size-cells = <0x00>;
		clocks = <0x2f 0x67>;
		clock-names = "div-clk";
		resets = <0x2f 0x67>;
		reset-names = "i2c";
		dmas = <0x3b 0x1a 0x3b 0x1a>;
		dma-names = "rx\0tx";
		nvidia,controller-id = <0x03>;
		status = "disabled";
		clock-frequency = <0x186a0>;
	};

	i2c@7000d000 {
		compatible = "nvidia,tegra210-i2c\0nvidia,tegra124-i2c";
		reg = <0x00 0x7000d000 0x00 0x100>;
		interrupts = <0x00 0x35 0x04>;
		#address-cells = <0x01>;
		#size-cells = <0x00>;
		clocks = <0x2f 0x2f 0x2f 0x128 0x2f 0x129>;
		clock-names = "div-clk\0cl_dvfs_ref\0cl_dvfs_soc";
		resets = <0x2f 0x2f>;
		reset-names = "i2c";
		dmas = <0x3b 0x18 0x3b 0x18>;
		dma-names = "rx\0tx";
		nvidia,controller-id = <0x04>;
		nvidia,scl-gpio = <0x40 0xc3 0x00>;
		nvidia,sda-gpio = <0x40 0xc4 0x00>;
		nvidia,require-cldvfs-clock;
		status = "okay";
		clock-frequency = <0x61a80>;

		max77620@3c {
			compatible = "maxim,max77620";
			reg = <0x3c>;
			interrupts = <0x00 0x56 0x00>;
			#interrupt-cells = <0x02>;
			interrupt-controller;
			gpio-controller;
			#gpio-cells = <0x02>;
			maxim,enable-clock32k-out;
			maxim,system-pmic-power-off;
			maxim,hot-die-threshold-temp = <0x1adb0>;
			#thermal-sensor-cells = <0x00>;
			pinctrl-names = "default";
			pinctrl-0 = <0x42>;
			linux,phandle = <0x3e>;
			phandle = <0x3e>;

			pinmux@0 {
				linux,phandle = <0x42>;
				phandle = <0x42>;

				pin_gpio0_7 {
					pins = "gpio0\0gpio7";
					function = "gpio";
				};

				pin_gpio1 {
					pins = "gpio1";
					function = "fps-out";
					drive-push-pull = <0x01>;
					maxim,fps-source = <0x00>;
					maxim,fps-power-up-period = <0x07>;
					maxim,fps-power-down-period = <0x00>;
				};

				pin_gpio2_3 {
					pins = "gpio2\0gpio3";
					function = "fps-out";
					drive-open-drain = <0x01>;
					maxim,fps-source = <0x00>;
				};

				pin_gpio4 {
					pins = "gpio4";
					function = "32k-out1";
				};

				pin_gpio5_6 {
					pins = "gpio5\0gpio6";
					function = "gpio";
					drive-push-pull = <0x01>;
				};
			};

			watchdog {
				maxim,wdt-timeout = <0x10>;
				maxim,wdt-clear-time = <0x0d>;
				status = "disabled";
			};

			fps {
				#address-cells = <0x01>;
				#size-cells = <0x00>;

				fps@0 {
					reg = <0x00>;
					maxim,fps-time-period = <0xa00>;
					maxim,fps-enable-input = <0x00>;
				};

				fps@1 {
					reg = <0x01>;
					maxim,fps-time-period = <0xa00>;
					maxim,fps-enable-input = <0x01>;
					maxim,enable-sleep;
				};

				fps@2 {
					reg = <0x02>;
					maxim,fps-enable-input = <0x00>;
				};
			};

			backup-battery {
				maxim,backup-battery-charging-current = <0x64>;
				maxim,backup-battery-charging-voltage = <0x2dc6c0>;
				maxim,backup-battery-output-resistor = <0x64>;
			};

			regulators {
				in-ldo0-1-supply = <0x43>;
				in-ldo7-8-supply = <0x43>;

				sd0 {
					regulator-name = "vdd_core";
					regulator-min-microvolt = <0x927c0>;
					regulator-max-microvolt = <0x155cc0>;
					regulator-enable-ramp-delay = <0x92>;
					regulator-disable-ramp-delay = <0xff0>;
					regulator-ramp-delay = <0x6b6c>;
					regulator-ramp-delay-scale = <0x12c>;
					regulator-boot-on;
					regulator-always-on;
					maxim,fps-source = <0x01>;
				};

				sd1 {
					regulator-name = "vddio-ddr";
					regulator-always-on;
					regulator-boot-on;
					maxim,fps-source = <0x00>;
					regulator-enable-ramp-delay = <0x82>;
					regulator-disable-ramp-delay = <0x23988>;
					regulator-ramp-delay = <0x6b6c>;
					regulator-ramp-delay-scale = <0x12c>;
				};

				sd2 {
					regulator-name = "vdd-pre-reg";
					regulator-min-microvolt = <0x149970>;
					regulator-max-microvolt = <0x149970>;
					regulator-enable-ramp-delay = <0xb0>;
					regulator-disable-ramp-delay = <0x7d00>;
					regulator-ramp-delay = <0x6b6c>;
					regulator-ramp-delay-scale = <0x15e>;
					regulator-always-on;
					regulator-boot-on;
					maxim,fps-source = <0x03>;
					linux,phandle = <0x43>;
					phandle = <0x43>;
				};

				sd3 {
					regulator-name = "vdd-1v8";
					regulator-min-microvolt = <0x1b7740>;
					regulator-max-microvolt = <0x1b7740>;
					regulator-enable-ramp-delay = <0xf2>;
					regulator-disable-ramp-delay = <0x1ccf0>;
					regulator-ramp-delay = <0x6b6c>;
					regulator-ramp-delay-scale = <0x168>;
					regulator-always-on;
					regulator-boot-on;
					maxim,fps-source = <0x00>;
					linux,phandle = <0x41>;
					phandle = <0x41>;
				};

				ldo0 {
					regulator-name = "avdd-sys";
					regulator-min-microvolt = <0x124f80>;
					regulator-max-microvolt = <0x124f80>;
					regulator-enable-ramp-delay = <0x1a>;
					regulator-disable-ramp-delay = <0x272>;
					regulator-ramp-delay = <0x186a0>;
					regulator-ramp-delay-scale = <0xc8>;
					regulator-boot-on;
					maxim,fps-source = <0x03>;
					linux,phandle = <0x4b>;
					phandle = <0x4b>;
				};

				ldo1 {
					regulator-name = "vdd-pex";
					regulator-min-microvolt = <0x106738>;
					regulator-max-microvolt = <0x106738>;
					regulator-enable-ramp-delay = <0x16>;
					regulator-disable-ramp-delay = <0x276>;
					regulator-ramp-delay = <0x186a0>;
					regulator-ramp-delay-scale = <0xc8>;
					maxim,fps-source = <0x03>;
				};

				ldo2 {
					regulator-name = "vddio-sdmmc3";
					regulator-min-microvolt = <0x1b7740>;
					regulator-max-microvolt = <0x325aa0>;
					regulator-enable-ramp-delay = <0x3e>;
					regulator-disable-ramp-delay = <0x28a>;
					regulator-ramp-delay = <0x186a0>;
					regulator-ramp-delay-scale = <0xc8>;
					maxim,fps-source = <0x03>;
				};

				ldo3 {
					regulator-name = "vdd-cam-hv";
					regulator-min-microvolt = <0x2ab980>;
					regulator-max-microvolt = <0x2ab980>;
					regulator-enable-ramp-delay = <0x32>;
					regulator-disable-ramp-delay = <0x456>;
					regulator-ramp-delay = <0x186a0>;
					regulator-ramp-delay-scale = <0xc8>;
					maxim,fps-source = <0x03>;
				};

				ldo4 {
					regulator-name = "vdd-rtc";
					regulator-min-microvolt = <0xcf850>;
					regulator-max-microvolt = <0xcf850>;
					regulator-enable-ramp-delay = <0x16>;
					regulator-disable-ramp-delay = <0x262>;
					regulator-ramp-delay = <0x186a0>;
					regulator-ramp-delay-scale = <0xc8>;
					regulator-always-on;
					regulator-boot-on;
					maxim,fps-source = <0x00>;
				};

				ldo5 {
					regulator-name = "avdd-ts-hv";
					regulator-min-microvolt = <0x325aa0>;
					regulator-max-microvolt = <0x325aa0>;
					regulator-enable-ramp-delay = <0x3e>;
					regulator-disable-ramp-delay = <0x280>;
					regulator-ramp-delay = <0x186a0>;
					regulator-ramp-delay-scale = <0xc8>;
					maxim,fps-source = <0x03>;
				};

				ldo6 {
					regulator-name = "vdd-ts";
					regulator-min-microvolt = <0x1b7740>;
					regulator-max-microvolt = <0x1b7740>;
					regulator-enable-ramp-delay = <0x24>;
					regulator-disable-ramp-delay = <0x2a2>;
					regulator-ramp-delay = <0x186a0>;
					regulator-ramp-delay-scale = <0xc8>;
					regulator-always-on;
					regulator-boot-on;
					maxim,fps-source = <0x00>;
					maxim,fps-power-up-period = <0x07>;
					maxim,fps-power-down-period = <0x00>;
				};

				ldo7 {
					regulator-name = "vdd-gen-pll-edp";
					regulator-min-microvolt = <0x100590>;
					regulator-max-microvolt = <0x100590>;
					regulator-enable-ramp-delay = <0x18>;
					regulator-disable-ramp-delay = <0xad0>;
					regulator-ramp-delay = <0x186a0>;
					regulator-ramp-delay-scale = <0xc8>;
					regulator-always-on;
					regulator-boot-on;
					maxim,fps-source = <0x01>;
				};

				ldo8 {
					regulator-name = "vdd-hdmi-dp";
					regulator-min-microvolt = <0x100590>;
					regulator-max-microvolt = <0x100590>;
					regulator-enable-ramp-delay = <0x16>;
					regulator-disable-ramp-delay = <0x488>;
					regulator-ramp-delay = <0x186a0>;
					regulator-ramp-delay-scale = <0xc8>;
					regulator-boot-on;
					maxim,fps-source = <0x03>;
				};
			};
		};
	};

	i2c@7000d100 {
		compatible = "nvidia,tegra210-i2c-dpaux";
		reg = <0x00 0x7000d100 0x00 0x100 0x00 0x545c0000 0x00 0x40000>;
		interrupts = <0x00 0x3f 0x04>;
		#address-cells = <0x01>;
		#size-cells = <0x00>;
		clocks = <0x2f 0xa6 0x2f 0xb5 0x2f 0xb6>;
		clock-names = "div-clk\0dpaux-clk\0sor-clk";
		resets = <0x2f 0xa6>;
		reset-names = "i2c";
		dmas = <0x3b 0x1e 0x3b 0x1e>;
		dma-names = "rx\0tx";
		nvidia,controller-id = <0x05>;
		status = "disabled";
		clock-frequency = <0x61a80>;
	};

	i2c@546c0000 {
		compatible = "nvidia,tegra210-i2c-vi";
		reg = <0x00 0x546c0000 0x00 0x34000>;
		interrupts = <0x00 0x11 0x04>;
		#address-cells = <0x01>;
		#size-cells = <0x00>;
		clocks = <0x2f 0xd0 0x2f 0x51 0x2f 0x1c>;
		clock-names = "div-clk\0slow-clk\0host1x-clk";
		resets = <0x2f 0xd0>;
		reset-names = "i2c";
		status = "disabled";
		clock-frequency = <0x61a80>;
	};

	sdhci@700b0600 {
		compatible = "nvidia,tegra210-sdhci\0nvidia,tegra132-sdhci";
		reg = <0x00 0x700b0600 0x00 0x200>;
		interrupts = <0x00 0x1f 0x04>;
		clocks = <0x2f 0x0f>;
		resets = <0x2f 0x0f>;
		reset-names = "sdhci";
		status = "okay";
		bus-width = <0x08>;
		non-removable;
	};

	sdhci@700b0000 {
		compatible = "nvidia,tegra210-sdhci\0nvidia,tegra132-sdhci";
		reg = <0x00 0x700b0000 0x00 0x200>;
		interrupts = <0x00 0x0e 0x04>;
		clocks = <0x2f 0x0e>;
		resets = <0x2f 0x0e>;
		reset-names = "sdhci";
		status = "okay";
		bus-width = <0x04>;
	};

	sdhci@700b0200 {
		compatible = "nvidia,tegra210-sdhci\0nvidia,tegra132-sdhci";
		reg = <0x00 0x700b0200 0x00 0x200>;
		interrupts = <0x00 0x0f 0x04>;
		clocks = <0x2f 0x09>;
		resets = <0x2f 0x09>;
		reset-names = "sdhci";
		status = "disabled";
	};

	sdhci@700b0400 {
		compatible = "nvidia,tegra210-sdhci\0nvidia,tegra132-sdhci";
		reg = <0x00 0x700b0400 0x00 0x200>;
		interrupts = <0x00 0x13 0x04>;
		clocks = <0x2f 0x45>;
		resets = <0x2f 0x45>;
		reset-names = "sdhci";
		status = "disabled";
	};

	efuse@7000f800 {
		compatible = "nvidia,tegra210-efuse";
		reg = <0x00 0x7000f800 0x00 0x400>;
		clocks = <0x2f 0xe6>;
		clock-names = "fuse";
		resets = <0x2f 0x27>;
		reset-names = "fuse";
		status = "okay";
		vpp_fuse-supply = <0x41>;
	};

	clock@0,70110000 {
		compatible = "nvidia,tegra210-dfll";
		reg = <0x00 0x70110000 0x00 0x100 0x00 0x70110000 0x00 0x100 0x00 0x70110100 0x00 0x100 0x00 0x70110200 0x00 0x100>;
		interrupts = <0x00 0x3e 0x04>;
		clocks = <0x2f 0x129 0x2f 0x128 0x2f 0x2f>;
		clock-names = "soc\0ref\0i2c";
		resets = <0x2f 0x40000000>;
		reset-names = "dvco";
		#clock-cells = <0x00>;
		clock-output-names = "dfllCPU_out";
		nvidia,sample-rate = <0x30d4>;
		nvidia,droop-ctrl = <0xf00>;
		nvidia,force-mode = <0x01>;
		nvidia,cf = <0x0a>;
		nvidia,ci = <0x00>;
		nvidia,cg = <0x02>;
		status = "disabled";
		linux,phandle = <0x47>;
		phandle = <0x47>;
	};

	usb@0,70098000 {
		compatible = "nvidia,tegra210-xusb";
		reg = <0x00 0x70098000 0x00 0x1000>;
		ranges;
		status = "disabled";
		#address-cells = <0x02>;
		#size-cells = <0x02>;

		usb-host@0,70090000 {
			compatible = "nvidia,tegra210-xhci";
			reg = <0x00 0x70090000 0x00 0x8000 0x00 0x70099000 0x00 0x1000>;
			interrupts = <0x00 0x27 0x04 0x00 0x31 0x04>;
			clocks = <0x2f 0x59 0x2f 0x11c 0x2f 0x11d 0x2f 0x9c 0x2f 0x16a 0x2f 0x11f 0x2f 0x122 0x2f 0x11e 0x2f 0xff 0x2f 0xe9 0x2f 0x107 0x2f 0x1e6>;
			clock-names = "xusb_host\0xusb_host_src\0xusb_falcon_src\0xusb_ss\0xusb_ss_div2\0xusb_ss_src\0xusb_hs_src\0xusb_fs_src\0pll_u_480m\0clk_m\0pll_e\0emc";
			resets = <0x2f 0x59 0x2f 0x9c 0x2f 0x8f>;
			reset-names = "xusb_host\0xusb_ss\0xusb_src";
			mboxes = <0x44>;
			mbox-names = "xusb";
			mc = <0x30 0x0c>;
		};

		mailbox {
			compatible = "nvidia,tegra210-xusb-mbox";
			interrupts = <0x00 0x28 0x04>;
			#mbox-cells = <0x00>;
			linux,phandle = <0x44>;
			phandle = <0x44>;
		};
	};

	padctl@0,7009f000 {
		compatible = "nvidia,tegra210-xusb-padctl";
		reg = <0x00 0x7009f000 0x00 0x1000>;
		clocks = <0x2f 0xd1 0x2f 0xd2 0x2f 0x107>;
		clock-names = "hsic_trk\0usb2_trk\0pll_e";
		resets = <0x2f 0x8e 0x2f 0xcc 0x2f 0xcd>;
		reset-names = "padctl\0sata_uphy\0pex_uphy";
		mboxes = <0x44>;
		mbox-names = "xusb";
		#phy-cells = <0x01>;
	};

	usb-device@0,700d0000 {
		compatible = "nvidia,tegra210-xudc";
		reg = <0x00 0x700d0000 0x00 0x8000 0x00 0x700d8000 0x00 0x1000 0x00 0x700d9000 0x00 0x1000>;
		interrupts = <0x00 0x2c 0x04>;
		clocks = <0x2f 0x121 0x2f 0x9c 0x2f 0xff 0x2f 0x122 0x2f 0x11e 0x2f 0x107>;
		clock-names = "xusb_dev\0xusb_ss\0pll_u_480M\0xusb_hs_src\0xusb_fs_src\0pll_e";
		resets = <0x2f 0x5f 0x2f 0x9c>;
		reset-names = "xusb_dev\0xusb_ss";
		mc = <0x30 0x0d>;
		status = "disabled";
	};

	usb@7d000000 {
		compatible = "nvidia,tegra30-ehci\0usb-ehci";
		reg = <0x00 0x7d000000 0x00 0x4000>;
		interrupts = <0x00 0x14 0x04>;
		phy_type = "utmi";
		clocks = <0x2f 0x16>;
		resets = <0x2f 0x16>;
		reset-names = "usb";
		nvidia,phy = <0x45>;
		status = "okay";
	};

	usb-phy@7d000000 {
		compatible = "nvidia,tegra30-usb-phy";
		reg = <0x00 0x7d000000 0x00 0x4000 0x00 0x7d000000 0x00 0x4000>;
		phy_type = "utmi";
		clocks = <0x2f 0x16 0x2f 0xfe 0x2f 0x16>;
		clock-names = "reg\0pll_u\0utmi-pads";
		nvidia,hssync-start-delay = <0x00>;
		nvidia,idle-wait-delay = <0x11>;
		nvidia,elastic-limit = <0x10>;
		nvidia,term-range-adj = <0x06>;
		nvidia,xcvr-setup = <0x09>;
		nvidia,xcvr-lsfslew = <0x00>;
		nvidia,xcvr-lsrslew = <0x03>;
		nvidia,hssquelch-level = <0x02>;
		nvidia,hsdiscon-level = <0x05>;
		nvidia,xcvr-hsslew = <0x0c>;
		status = "okay";
		vbus-supply = <0x46>;
		linux,phandle = <0x45>;
		phandle = <0x45>;
	};

	arm-pmu {
		compatible = "arm,armv8-pmuv3";
		interrupts = <0x00 0x90 0x04 0x00 0x91 0x04 0x00 0x92 0x04 0x00 0x93 0x04>;
	};

	cpus {
		#address-cells = <0x02>;
		#size-cells = <0x00>;

		cpu@0 {
			device_type = "cpu";
			compatible = "arm,cortex-a57\0arm,armv8";
			reg = <0x00 0x00>;
			enable-method = "psci";
			clocks = <0x2f 0x126 0x2f 0x127 0x2f 0x103 0x2f 0xf7 0x2f 0x1c4 0x47>;
			clock-names = "cpu_g\0cpu_lp\0pll_x\0pll_p\0emc\0dfll";
			clock-latency = <0x493e0>;
			cpu-idle-states = <0x48>;
			next-level-cache = <0x49>;
			current = <0xee20 0x1ad92 0x2a062 0x39332 0x476d0 0x56874 0x6476c 0x721b4 0x80552 0x8ec74 0x8bef2 0x8dfa4 0xa0820 0xbcd0e 0xdaf2a 0x10002c 0x12d89c 0x14be32 0x14fc12 0x15c282>;
		};

		cpu@1 {
			device_type = "cpu";
			compatible = "arm,cortex-a57\0arm,armv8";
			reg = <0x00 0x01>;
			enable-method = "psci";
			cpu-idle-states = <0x48>;
			next-level-cache = <0x49>;
			current = <0xee20 0x1ad92 0x2a062 0x39332 0x476d0 0x56874 0x6476c 0x721b4 0x80552 0x8ec74 0x8bef2 0x8dfa4 0xa0820 0xbcd0e 0xdaf2a 0x10002c 0x12d89c 0x14be32 0x14fc12 0x15c282>;
		};

		cpu@2 {
			device_type = "cpu";
			compatible = "arm,cortex-a57\0arm,armv8";
			reg = <0x00 0x02>;
			enable-method = "psci";
			cpu-idle-states = <0x48>;
			next-level-cache = <0x49>;
			current = <0xee20 0x1ad92 0x2a062 0x39332 0x476d0 0x56874 0x6476c 0x721b4 0x80552 0x8ec74 0x8bef2 0x8dfa4 0xa0820 0xbcd0e 0xdaf2a 0x10002c 0x12d89c 0x14be32 0x14fc12 0x15c282>;
		};

		cpu@3 {
			device_type = "cpu";
			compatible = "arm,cortex-a57\0arm,armv8";
			reg = <0x00 0x03>;
			enable-method = "psci";
			cpu-idle-states = <0x48>;
			next-level-cache = <0x49>;
			current = <0xee20 0x1ad92 0x2a062 0x39332 0x476d0 0x56874 0x6476c 0x721b4 0x80552 0x8ec74 0x8bef2 0x8dfa4 0xa0820 0xbcd0e 0xdaf2a 0x10002c 0x12d89c 0x14be32 0x14fc12 0x15c282>;
		};

		idle-states {
			entry-method = "psci";

			c7 {
				compatible = "arm,idle-state";
				arm,psci-suspend-param = <0x10007>;
				wakeup-latency-us = <0x82>;
				min-residency-us = <0x3e8>;
				idle-state-name = "c7-cpu-powergate";
				status = "okay";
				linux,phandle = <0x48>;
				phandle = <0x48>;
			};
		};

		l2-cache {
			compatible = "cache";
			linux,phandle = <0x49>;
			phandle = <0x49>;
		};
	};

	psci {
		compatible = "arm,psci-1.0";
		method = "smc";
	};

	timer {
		compatible = "arm,armv8-timer";
		interrupts = <0x01 0x0d 0xf08 0x01 0x0e 0xf08 0x01 0x0b 0xf08 0x01 0x0a 0xf08>;
		interrupt-parent = <0x35>;
		status = "okay";
	};

	dram_therm {
		compatible = "nvidia,tegra-dram-therm";
		#cooling-cells = <0x02>;
		status = "okay";
		linux,phandle = <0x2c>;
		phandle = <0x2c>;
	};

	dfll-cdev-cap {
		compatible = "nvidia,tegra-dfll-cdev-action";
		act-dev = <0x47>;
		cdev-type = "DFLL-cap";
		#cooling-cells = <0x02>;
		linux,phandle = <0x1a>;
		phandle = <0x1a>;
	};

	dfll-cdev-floor {
		compatible = "nvidia,tegra-dfll-cdev-action";
		act-dev = <0x47>;
		cdev-type = "DFLL-floor";
		#cooling-cells = <0x02>;
		linux,phandle = <0x15>;
		phandle = <0x15>;
	};

	soctherm@0,700e2000 {
		compatible = "nvidia,tegra210-soctherm";
		reg = <0x00 0x700e2000 0x00 0x600 0x00 0x60006000 0x00 0x400 0x00 0x70040000 0x00 0x200>;
		reg-names = "soctherm-reg\0car-reg\0ccroc-reg";
		interrupts = <0x00 0x30 0x04 0x00 0x33 0x04>;
		clocks = <0x2f 0x64 0x2f 0x4e>;
		clock-names = "tsensor\0soctherm";
		resets = <0x2f 0x4e>;
		reset-names = "soctherm";
		#thermal-sensor-cells = <0x01>;
		#interrupt-cells = <0x02>;
		interrupt-controller;
		linux,phandle = <0x05>;
		phandle = <0x05>;

		throttle-cfgs {

			heavy {
				priority = <0x64>;
				cpu-throt-depth = <0x55>;
				gpu-throt-level = <0x02>;
			};

			oc1 {
				alarm-filter = <0x4dd1e0>;
				alarm-cnt-threshold = <0x64>;
				polarity = <0x01>;
				priority = <0x46>;
				cpu-throt-depth = <0x4b>;
			};

			oc3 {
				alarm-filter = <0x4dd1e0>;
				alarm-cnt-threshold = <0x0f>;
				polarity = <0x01>;
				priority = <0x32>;
				cpu-throt-depth = <0x4b>;
			};
		};

		hw-trips {

			sensor-groups {

				cpu {
					therm-temp = <0x19258>;
					throt-temp = <0x180c4>;
				};

				gpu {
					therm-temp = <0x1944c>;
					throt-temp = <0x186a0>;
				};

				mem {
					therm-temp = <0x1944c>;
				};

				pll {
					therm-temp = <0x19a28>;
				};
			};
		};
	};

	core_dvfs_cdev_floor {
		compatible = "nvidia,tegra-core-cdev-action";
		cdev-type = "CORE-floor";
		#cooling-cells = <0x02>;
		linux,phandle = <0x1d>;
		phandle = <0x1d>;
	};

	core_dvfs_cdev_cap {
		compatible = "nvidia,tegra-core-cdev-action";
		cdev-type = "CORE-cap";
		#cooling-cells = <0x02>;
		linux,phandle = <0x1f>;
		phandle = <0x1f>;
	};

	balanced_cpu {
		compatible = "nvidia,balanced-throttle";
		clocks = <0x2f 0x1a2 0x2f 0x1b9 0x2f 0x1d2>;
		clock-names = "cap.throttle.c3bus\0cap.throttle.sclk\0cap.throttle.emc";
		balanced-states = <0x31>;
		#cooling-cells = <0x02>;
	};

	balanced_gpu {
		compatible = "nvidia,balanced-throttle";
		clocks = <0x2f 0x1a2 0x2f 0x1b9 0x2f 0x1d2>;
		clock-names = "cap.throttle.c3bus\0cap.throttle.sclk\0cap.throttle.emc";
		balanced-states = <0x32>;
		#cooling-cells = <0x02>;
	};

	gpio-keys {
		compatible = "gpio-keys";
		gpio-keys,name = "gpio-keys";

		power {
			label = "Power";
			gpios = <0x40 0xbd 0x01>;
			linux,code = <0x74>;
			gpio-key,wakeup;
		};

		sw_lid {
			label = "SW LID";
			gpios = <0x40 0x0c 0x01>;
			linux,code = <0x00>;
			linux,input-type = <0x05>;
			gpio-key,wakeup;
			debounce-interval = <0x12c>;
		};
	};

	pwm_regulators {
		compatible = "simple-bus";
		#address-cells = <0x01>;
		#size-cells = <0x00>;

		pwm-regulator@0 {
			status = "okay";
			reg = <0x00>;
			compatible = "regulator-pwm";
			regulator-name = "vdd_cpu";
			regulator-min-microvolt = <0xad188>;
			regulator-max-microvolt = <0x142508>;
			regulator-init-microvolt = <0xf4240>;
			regulator-always-on;
			regulator-boot-on;
			regulator-n-voltages = <0x21>;
			voltage-time-sel = <0x50>;
		};

		pwm-regulator@1 {
			status = "okay";
			reg = <0x01>;
			compatible = "regulator-pwm";
			pwms = <0x4a 0x01 0x1310>;
			regulator-name = "vdd_gpu";
			regulator-min-microvolt = <0xad570>;
			regulator-max-microvolt = <0x142440>;
			regulator-init-microvolt = <0xf4240>;
			regulator-ramp-delay = <0x1f4>;
			regulator-n-voltages = <0x3e>;
			regulator-enable-ramp-delay = <0x3e8>;
			regulator-boot-on;
			enable-gpio = <0x3e 0x06 0x00>;
		};
	};

	regulators {
		compatible = "simple-bus";
		device_type = "fixed-regulators";
		#address-cells = <0x01>;
		#size-cells = <0x00>;

		regulator@0 {
			compatible = "regulator-fixed";
			reg = <0x00>;
			regulator-name = "vdd-ac-bat";
			regulator-min-microvolt = <0x4c4b40>;
			regulator-max-microvolt = <0x4c4b40>;
			regulator-always-on;
		};

		regulator@1 {
			compatible = "regulator-fixed-sync";
			reg = <0x01>;
			regulator-name = "vdd-3v3";
			regulator-min-microvolt = <0x325aa0>;
			regulator-max-microvolt = <0x325aa0>;
			regulator-enable-ramp-delay = <0xa0>;
			regulator-disable-ramp-delay = <0x2710>;
			regulator-always-on;
			gpio = <0x3e 0x03 0x00>;
			enable-active-high;
			linux,phandle = <0x4c>;
			phandle = <0x4c>;
		};

		regulator@2 {
			compatible = "regulator-fixed-sync";
			reg = <0x02>;
			regulator-name = "max77620-gpio7";
			regulator-always-on;
			regulator-min-microvolt = <0x124f80>;
			regulator-max-microvolt = <0x124f80>;
			regulator-enable-ramp-delay = <0xf0>;
			regulator-disable-ramp-delay = <0x2c4c>;
			regulator-boot-on;
			gpio = <0x3e 0x07 0x00>;
			enable-active-high;
			vin-supply = <0x4b>;
		};

		regulator@3 {
			compatible = "regulator-fixed-sync";
			reg = <0x03>;
			regulator-name = "lcd-bl-en";
			regulator-min-microvolt = <0x1b7740>;
			regulator-max-microvolt = <0x1b7740>;
			regulator-boot-on;
			gpio = <0x40 0xa9 0x00>;
			enable-active-high;
		};

		regulator@4 {
			compatible = "regulator-fixed-sync";
			reg = <0x04>;
			regulator-name = "en-vdd-sd";
			regulator-min-microvolt = <0x325aa0>;
			regulator-max-microvolt = <0x325aa0>;
			regulator-enable-ramp-delay = <0x1d8>;
			regulator-disable-ramp-delay = <0x1310>;
			gpio = <0x40 0xcc 0x00>;
			enable-active-high;
			vin-supply = <0x4c>;
		};

		regulator@5 {
			compatible = "regulator-fixed-sync";
			reg = <0x05>;
			regulator-name = "en-vdd-cam";
			regulator-min-microvolt = <0x1b7740>;
			regulator-max-microvolt = <0x1b7740>;
			gpio = <0x40 0x94 0x00>;
			enable-active-high;
		};

		regulator@6 {
			compatible = "regulator-fixed-sync";
			reg = <0x06>;
			regulator-name = "vdd-sys-boost";
			regulator-min-microvolt = <0x4c4b40>;
			regulator-max-microvolt = <0x4c4b40>;
			regulator-enable-ramp-delay = <0xc12>;
			regulator-always-on;
			gpio = <0x3e 0x01 0x00>;
			enable-active-high;
			linux,phandle = <0x4d>;
			phandle = <0x4d>;
		};

		regulator@7 {
			compatible = "regulator-fixed-sync";
			reg = <0x07>;
			regulator-name = "vdd-hdmi";
			regulator-min-microvolt = <0x4c4b40>;
			regulator-max-microvolt = <0x4c4b40>;
			regulator-enable-ramp-delay = <0x1d4>;
			regulator-disable-ramp-delay = <0x32c8>;
			gpio = <0x40 0xe7 0x00>;
			enable-active-high;
			vin-supply = <0x4d>;
		};

		regulator@8 {
			compatible = "regulator-fixed";
			reg = <0x08>;
			regulator-name = "vdd-cpu-fixed";
			regulator-min-microvolt = <0xf4240>;
			regulator-max-microvolt = <0xf4240>;
		};

		regulator@9 {
			compatible = "regulator-fixed-sync";
			reg = <0x09>;
			regulator-name = "aux-3v3";
			regulator-min-microvolt = <0x325aa0>;
			regulator-max-microvolt = <0x325aa0>;
		};

		regulator@10 {
			compatible = "regulator-fixed-sync";
			reg = <0x0a>;
			regulator-name = "snsr_pm";
			enable-active-high;
			regulator-min-microvolt = <0x325aa0>;
			regulator-max-microvolt = <0x325aa0>;
		};

		regulator@11 {
			compatible = "regulator-fixed-sync";
			reg = <0x0b>;
			regulator-name = "vdd-usb-5v0";
			regulator-min-microvolt = <0x4c4b40>;
			regulator-max-microvolt = <0x4c4b40>;
			vin-supply = <0x4c>;
			regulator-always-on;
			enable-active-high;
			linux,phandle = <0x46>;
			phandle = <0x46>;
		};

		regulator@12 {
			compatible = "regulator-fixed-sync";
			reg = <0x0c>;
			regulator-name = "vdd-disp-3v0";
			regulator-min-microvolt = <0x2dc6c0>;
			regulator-max-microvolt = <0x2dc6c0>;
			gpio = <0x40 0x43 0x00>;
			regulator-always-on;
			enable-active-high;
			regulator-enable-ramp-delay = <0xe8>;
		};

		regulator@13 {
			compatible = "regulator-fixed-sync";
			reg = <0x0d>;
			regulator-name = "vdd-fan";
			regulator-min-microvolt = <0x4c4b40>;
			regulator-max-microvolt = <0x4c4b40>;
			gpio = <0x40 0x24 0x00>;
			regulator-always-on;
			enable-active-high;
			regulator-enable-ramp-delay = <0x11c>;
			regulator-disable-ramp-delay = <0x1838>;
		};

		regulator@14 {
			compatible = "regulator-fixed-sync";
			reg = <0x0e>;
			regulator-name = "usb-vbus1";
			regulator-min-microvolt = <0x4c4b40>;
			regulator-max-microvolt = <0x4c4b40>;
			gpio = <0x40 0xe4 0x00>;
			enable-active-high;
			gpio-open-drain;
		};

		regulator@15 {
			compatible = "regulator-fixed-sync";
			reg = <0x0f>;
			regulator-name = "usb-vbus2";
			regulator-min-microvolt = <0x4c4b40>;
			regulator-max-microvolt = <0x4c4b40>;
			gpio = <0x40 0xe5 0x00>;
			enable-active-high;
			gpio-open-drain;
		};

		regulator@16 {
			compatible = "regulator-fixed-sync";
			reg = <0x10>;
			regulator-name = "usb-vbus3";
			regulator-min-microvolt = <0x4c4b40>;
			regulator-max-microvolt = <0x4c4b40>;
			gpio = <0x40 0x1c 0x00>;
			enable-active-high;
			gpio-open-drain;
		};

		regulator@101 {
			compatible = "regulator-fixed-sync";
			reg = <0x65>;
			status = "disabled";
			regulator-name = "vdd_cdc_1v2_aud";
			regulator-min-microvolt = <0x124f80>;
			regulator-max-microvolt = <0x124f80>;
			enable-active-high;
			startup-delay-us = <0x3d090>;
		};
	};
};
